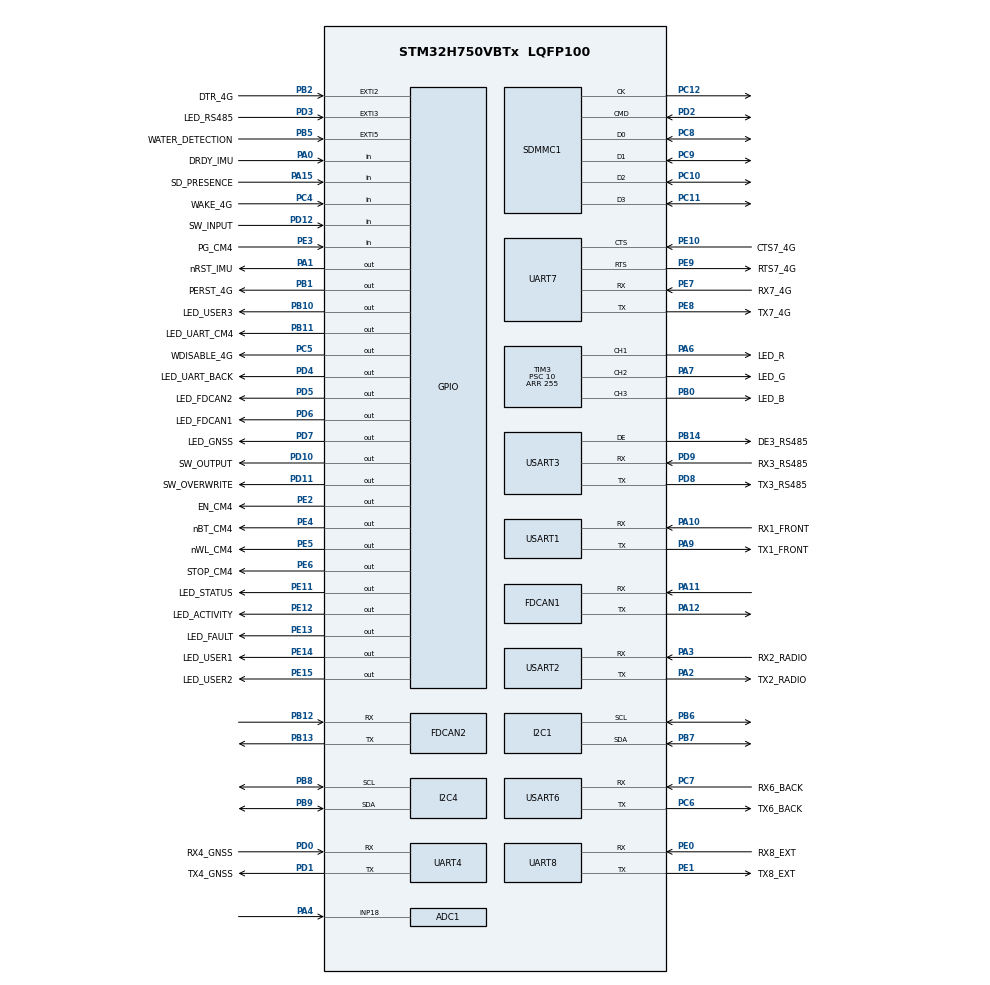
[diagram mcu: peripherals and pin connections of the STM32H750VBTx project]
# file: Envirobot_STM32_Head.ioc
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ADC1.Channel-2\#ChannelRegularConversion=ADC_CHANNEL_18
ADC1.ClockPrescaler=ADC_CLOCK_ASYNC_DIV32
ADC1.NbrOfConversionFlag=1
ADC1.OffsetNumber-2\#ChannelRegularConversion=ADC_OFFSET_NONE
ADC1.OffsetSignedSaturation-2\#ChannelRegularConversion=DISABLE
ADC1.Rank-2\#ChannelRegularConversion=1
ADC1.SamplingTime-2\#ChannelRegularConversion=ADC_SAMPLETIME_16CYCLES_5
ADC1.master=1
ADC3.Channel-0\#ChannelRegularConversion=ADC_CHANNEL_VREFINT
ADC3.ClockPrescaler=ADC_CLOCK_ASYNC_DIV32
ADC3.ClockPrescalerADC3=ADC_CLOCK_ASYNC_DIV32
ADC3.NbrOfConversionFlag=1
ADC3.OffsetNumber-0\#ChannelRegularConversion=ADC_OFFSET_NONE
ADC3.OffsetSignedSaturation-0\#ChannelRegularConversion=DISABLE
ADC3.Rank-0\#ChannelRegularConversion=1
ADC3.Resolution=ADC_RESOLUTION_12B
ADC3.SamplingTime-0\#ChannelRegularConversion=ADC_SAMPLETIME_16CYCLES_5
Dma.I2C1_RX.9.Direction=DMA_PERIPH_TO_MEMORY
Dma.I2C1_RX.9.EventEnable=DISABLE
Dma.I2C1_RX.9.FIFOMode=DMA_FIFOMODE_DISABLE
Dma.I2C1_RX.9.Instance=DMA2_Stream1
Dma.I2C1_RX.9.MemDataAlignment=DMA_MDATAALIGN_BYTE
Dma.I2C1_RX.9.MemInc=DMA_MINC_ENABLE
Dma.I2C1_RX.9.Mode=DMA_NORMAL
Dma.I2C1_RX.9.PeriphDataAlignment=DMA_PDATAALIGN_BYTE
Dma.I2C1_RX.9.PeriphInc=DMA_PINC_DISABLE
Dma.I2C1_RX.9.Polarity=HAL_DMAMUX_REQ_GEN_RISING
Dma.I2C1_RX.9.Priority=DMA_PRIORITY_LOW
Dma.I2C1_RX.9.RequestNumber=1
Dma.I2C1_RX.9.SignalID=NONE
Dma.I2C1_RX.9.SyncEnable=DISABLE
Dma.I2C1_RX.9.SyncPolarity=HAL_DMAMUX_SYNC_NO_EVENT
Dma.I2C1_RX.9.SyncRequestNumber=1
Dma.I2C1_RX.9.SyncSignalID=NONE
Dma.I2C1_TX.8.Direction=DMA_MEMORY_TO_PERIPH
Dma.I2C1_TX.8.EventEnable=DISABLE
Dma.I2C1_TX.8.FIFOMode=DMA_FIFOMODE_DISABLE
Dma.I2C1_TX.8.Instance=DMA2_Stream0
Dma.I2C1_TX.8.MemDataAlignment=DMA_MDATAALIGN_BYTE
Dma.I2C1_TX.8.MemInc=DMA_MINC_ENABLE
Dma.I2C1_TX.8.Mode=DMA_NORMAL
Dma.I2C1_TX.8.PeriphDataAlignment=DMA_PDATAALIGN_BYTE
Dma.I2C1_TX.8.PeriphInc=DMA_PINC_DISABLE
Dma.I2C1_TX.8.Polarity=HAL_DMAMUX_REQ_GEN_RISING
Dma.I2C1_TX.8.Priority=DMA_PRIORITY_LOW
Dma.I2C1_TX.8.RequestNumber=1
Dma.I2C1_TX.8.SignalID=NONE
Dma.I2C1_TX.8.SyncEnable=DISABLE
Dma.I2C1_TX.8.SyncPolarity=HAL_DMAMUX_SYNC_NO_EVENT
Dma.I2C1_TX.8.SyncRequestNumber=1
Dma.I2C1_TX.8.SyncSignalID=NONE
Dma.Request0=USART1_TX
Dma.Request1=USART1_RX
Dma.Request10=UART4_TX
Dma.Request11=UART4_RX
Dma.Request12=UART7_TX
Dma.Request13=UART7_RX
Dma.Request14=UART8_TX
Dma.Request15=UART8_RX
Dma.Request2=USART2_TX
Dma.Request3=USART2_RX
Dma.Request4=USART3_TX
Dma.Request5=USART3_RX
Dma.Request6=USART6_TX
Dma.Request7=USART6_RX
Dma.Request8=I2C1_TX
Dma.Request9=I2C1_RX
Dma.UART4_RX.11.Direction=DMA_PERIPH_TO_MEMORY
Dma.UART4_RX.11.EventEnable=DISABLE
Dma.UART4_RX.11.FIFOMode=DMA_FIFOMODE_DISABLE
Dma.UART4_RX.11.Instance=DMA2_Stream3
Dma.UART4_RX.11.MemDataAlignment=DMA_MDATAALIGN_BYTE
Dma.UART4_RX.11.MemInc=DMA_MINC_ENABLE
Dma.UART4_RX.11.Mode=DMA_CIRCULAR
Dma.UART4_RX.11.PeriphDataAlignment=DMA_PDATAALIGN_BYTE
Dma.UART4_RX.11.PeriphInc=DMA_PINC_DISABLE
Dma.UART4_RX.11.Polarity=HAL_DMAMUX_REQ_GEN_RISING
Dma.UART4_RX.11.Priority=DMA_PRIORITY_LOW
Dma.UART4_RX.11.RequestNumber=1
Dma.UART4_RX.11.SignalID=NONE
Dma.UART4_RX.11.SyncEnable=DISABLE
Dma.UART4_RX.11.SyncPolarity=HAL_DMAMUX_SYNC_NO_EVENT
Dma.UART4_RX.11.SyncRequestNumber=1
Dma.UART4_RX.11.SyncSignalID=NONE
Dma.UART4_TX.10.Direction=DMA_MEMORY_TO_PERIPH
Dma.UART4_TX.10.EventEnable=DISABLE
Dma.UART4_TX.10.FIFOMode=DMA_FIFOMODE_DISABLE
Dma.UART4_TX.10.Instance=DMA2_Stream2
Dma.UART4_TX.10.MemDataAlignment=DMA_MDATAALIGN_BYTE
Dma.UART4_TX.10.MemInc=DMA_MINC_ENABLE
Dma.UART4_TX.10.Mode=DMA_NORMAL
Dma.UART4_TX.10.PeriphDataAlignment=DMA_PDATAALIGN_BYTE
Dma.UART4_TX.10.PeriphInc=DMA_PINC_DISABLE
Dma.UART4_TX.10.Polarity=HAL_DMAMUX_REQ_GEN_RISING
Dma.UART4_TX.10.Priority=DMA_PRIORITY_LOW
Dma.UART4_TX.10.RequestNumber=1
Dma.UART4_TX.10.SignalID=NONE
Dma.UART4_TX.10.SyncEnable=DISABLE
Dma.UART4_TX.10.SyncPolarity=HAL_DMAMUX_SYNC_NO_EVENT
Dma.UART4_TX.10.SyncRequestNumber=1
Dma.UART4_TX.10.SyncSignalID=NONE
Dma.UART7_RX.13.Direction=DMA_PERIPH_TO_MEMORY
Dma.UART7_RX.13.EventEnable=DISABLE
Dma.UART7_RX.13.FIFOMode=DMA_FIFOMODE_DISABLE
Dma.UART7_RX.13.Instance=DMA2_Stream5
Dma.UART7_RX.13.MemDataAlignment=DMA_MDATAALIGN_BYTE
Dma.UART7_RX.13.MemInc=DMA_MINC_ENABLE
Dma.UART7_RX.13.Mode=DMA_CIRCULAR
Dma.UART7_RX.13.PeriphDataAlignment=DMA_PDATAALIGN_BYTE
Dma.UART7_RX.13.PeriphInc=DMA_PINC_DISABLE
Dma.UART7_RX.13.Polarity=HAL_DMAMUX_REQ_GEN_RISING
Dma.UART7_RX.13.Priority=DMA_PRIORITY_LOW
Dma.UART7_RX.13.RequestNumber=1
Dma.UART7_RX.13.SignalID=NONE
Dma.UART7_RX.13.SyncEnable=DISABLE
Dma.UART7_RX.13.SyncPolarity=HAL_DMAMUX_SYNC_NO_EVENT
Dma.UART7_RX.13.SyncRequestNumber=1
Dma.UART7_RX.13.SyncSignalID=NONE
Dma.UART7_TX.12.Direction=DMA_MEMORY_TO_PERIPH
Dma.UART7_TX.12.EventEnable=DISABLE
Dma.UART7_TX.12.FIFOMode=DMA_FIFOMODE_DISABLE
Dma.UART7_TX.12.Instance=DMA2_Stream4
Dma.UART7_TX.12.MemDataAlignment=DMA_MDATAALIGN_BYTE
Dma.UART7_TX.12.MemInc=DMA_MINC_ENABLE
Dma.UART7_TX.12.Mode=DMA_NORMAL
Dma.UART7_TX.12.PeriphDataAlignment=DMA_PDATAALIGN_BYTE
Dma.UART7_TX.12.PeriphInc=DMA_PINC_DISABLE
Dma.UART7_TX.12.Polarity=HAL_DMAMUX_REQ_GEN_RISING
Dma.UART7_TX.12.Priority=DMA_PRIORITY_LOW
Dma.UART7_TX.12.RequestNumber=1
Dma.UART7_TX.12.SignalID=NONE
Dma.UART7_TX.12.SyncEnable=DISABLE
Dma.UART7_TX.12.SyncPolarity=HAL_DMAMUX_SYNC_NO_EVENT
Dma.UART7_TX.12.SyncRequestNumber=1
Dma.UART7_TX.12.SyncSignalID=NONE
Dma.UART8_RX.15.Direction=DMA_PERIPH_TO_MEMORY
Dma.UART8_RX.15.EventEnable=DISABLE
Dma.UART8_RX.15.FIFOMode=DMA_FIFOMODE_DISABLE
Dma.UART8_RX.15.Instance=DMA2_Stream7
Dma.UART8_RX.15.MemDataAlignment=DMA_MDATAALIGN_BYTE
Dma.UART8_RX.15.MemInc=DMA_MINC_ENABLE
Dma.UART8_RX.15.Mode=DMA_CIRCULAR
Dma.UART8_RX.15.PeriphDataAlignment=DMA_PDATAALIGN_BYTE
Dma.UART8_RX.15.PeriphInc=DMA_PINC_DISABLE
Dma.UART8_RX.15.Polarity=HAL_DMAMUX_REQ_GEN_RISING
Dma.UART8_RX.15.Priority=DMA_PRIORITY_LOW
Dma.UART8_RX.15.RequestNumber=1
Dma.UART8_RX.15.SignalID=NONE
Dma.UART8_RX.15.SyncEnable=DISABLE
Dma.UART8_RX.15.SyncPolarity=HAL_DMAMUX_SYNC_NO_EVENT
Dma.UART8_RX.15.SyncRequestNumber=1
Dma.UART8_RX.15.SyncSignalID=NONE
Dma.UART8_TX.14.Direction=DMA_MEMORY_TO_PERIPH
Dma.UART8_TX.14.EventEnable=DISABLE
Dma.UART8_TX.14.FIFOMode=DMA_FIFOMODE_DISABLE
Dma.UART8_TX.14.Instance=DMA2_Stream6
Dma.UART8_TX.14.MemDataAlignment=DMA_MDATAALIGN_BYTE
Dma.UART8_TX.14.MemInc=DMA_MINC_ENABLE
Dma.UART8_TX.14.Mode=DMA_NORMAL
Dma.UART8_TX.14.PeriphDataAlignment=DMA_PDATAALIGN_BYTE
Dma.UART8_TX.14.PeriphInc=DMA_PINC_DISABLE
Dma.UART8_TX.14.Polarity=HAL_DMAMUX_REQ_GEN_RISING
Dma.UART8_TX.14.Priority=DMA_PRIORITY_LOW
Dma.UART8_TX.14.RequestNumber=1
Dma.UART8_TX.14.SignalID=NONE
Dma.UART8_TX.14.SyncEnable=DISABLE
Dma.UART8_TX.14.SyncPolarity=HAL_DMAMUX_SYNC_NO_EVENT
Dma.UART8_TX.14.SyncRequestNumber=1
Dma.UART8_TX.14.SyncSignalID=NONE
Dma.USART1_RX.1.Direction=DMA_PERIPH_TO_MEMORY
Dma.USART1_RX.1.EventEnable=DISABLE
Dma.USART1_RX.1.FIFOMode=DMA_FIFOMODE_DISABLE
Dma.USART1_RX.1.Instance=DMA1_Stream1
Dma.USART1_RX.1.MemDataAlignment=DMA_MDATAALIGN_BYTE
Dma.USART1_RX.1.MemInc=DMA_MINC_ENABLE
Dma.USART1_RX.1.Mode=DMA_CIRCULAR
Dma.USART1_RX.1.PeriphDataAlignment=DMA_PDATAALIGN_BYTE
Dma.USART1_RX.1.PeriphInc=DMA_PINC_DISABLE
Dma.USART1_RX.1.Polarity=HAL_DMAMUX_REQ_GEN_RISING
Dma.USART1_RX.1.Priority=DMA_PRIORITY_LOW
Dma.USART1_RX.1.RequestNumber=1
Dma.USART1_RX.1.SignalID=NONE
Dma.USART1_RX.1.SyncEnable=DISABLE
Dma.USART1_RX.1.SyncPolarity=HAL_DMAMUX_SYNC_NO_EVENT
Dma.USART1_RX.1.SyncRequestNumber=1
Dma.USART1_RX.1.SyncSignalID=NONE
Dma.USART1_TX.0.Direction=DMA_MEMORY_TO_PERIPH
Dma.USART1_TX.0.EventEnable=DISABLE
Dma.USART1_TX.0.FIFOMode=DMA_FIFOMODE_DISABLE
Dma.USART1_TX.0.Instance=DMA1_Stream0
Dma.USART1_TX.0.MemDataAlignment=DMA_MDATAALIGN_BYTE
Dma.USART1_TX.0.MemInc=DMA_MINC_ENABLE
Dma.USART1_TX.0.Mode=DMA_NORMAL
Dma.USART1_TX.0.PeriphDataAlignment=DMA_PDATAALIGN_BYTE
Dma.USART1_TX.0.PeriphInc=DMA_PINC_DISABLE
Dma.USART1_TX.0.Polarity=HAL_DMAMUX_REQ_GEN_RISING
Dma.USART1_TX.0.Priority=DMA_PRIORITY_LOW
Dma.USART1_TX.0.RequestNumber=1
Dma.USART1_TX.0.SignalID=NONE
Dma.USART1_TX.0.SyncEnable=DISABLE
Dma.USART1_TX.0.SyncPolarity=HAL_DMAMUX_SYNC_NO_EVENT
Dma.USART1_TX.0.SyncRequestNumber=1
Dma.USART1_TX.0.SyncSignalID=NONE
Dma.USART2_RX.3.Direction=DMA_PERIPH_TO_MEMORY
Dma.USART2_RX.3.EventEnable=DISABLE
Dma.USART2_RX.3.FIFOMode=DMA_FIFOMODE_DISABLE
Dma.USART2_RX.3.Instance=DMA1_Stream3
Dma.USART2_RX.3.MemDataAlignment=DMA_MDATAALIGN_BYTE
Dma.USART2_RX.3.MemInc=DMA_MINC_ENABLE
Dma.USART2_RX.3.Mode=DMA_CIRCULAR
Dma.USART2_RX.3.PeriphDataAlignment=DMA_PDATAALIGN_BYTE
Dma.USART2_RX.3.PeriphInc=DMA_PINC_DISABLE
Dma.USART2_RX.3.Polarity=HAL_DMAMUX_REQ_GEN_RISING
Dma.USART2_RX.3.Priority=DMA_PRIORITY_LOW
Dma.USART2_RX.3.RequestNumber=1
Dma.USART2_RX.3.SignalID=NONE
Dma.USART2_RX.3.SyncEnable=DISABLE
Dma.USART2_RX.3.SyncPolarity=HAL_DMAMUX_SYNC_NO_EVENT
Dma.USART2_RX.3.SyncRequestNumber=1
Dma.USART2_RX.3.SyncSignalID=NONE
Dma.USART2_TX.2.Direction=DMA_MEMORY_TO_PERIPH
Dma.USART2_TX.2.EventEnable=DISABLE
Dma.USART2_TX.2.FIFOMode=DMA_FIFOMODE_DISABLE
Dma.USART2_TX.2.Instance=DMA1_Stream2
Dma.USART2_TX.2.MemDataAlignment=DMA_MDATAALIGN_BYTE
Dma.USART2_TX.2.MemInc=DMA_MINC_ENABLE
Dma.USART2_TX.2.Mode=DMA_NORMAL
Dma.USART2_TX.2.PeriphDataAlignment=DMA_PDATAALIGN_BYTE
Dma.USART2_TX.2.PeriphInc=DMA_PINC_DISABLE
Dma.USART2_TX.2.Polarity=HAL_DMAMUX_REQ_GEN_RISING
Dma.USART2_TX.2.Priority=DMA_PRIORITY_LOW
Dma.USART2_TX.2.RequestNumber=1
Dma.USART2_TX.2.SignalID=NONE
Dma.USART2_TX.2.SyncEnable=DISABLE
Dma.USART2_TX.2.SyncPolarity=HAL_DMAMUX_SYNC_NO_EVENT
Dma.USART2_TX.2.SyncRequestNumber=1
Dma.USART2_TX.2.SyncSignalID=NONE
Dma.USART3_RX.5.Direction=DMA_PERIPH_TO_MEMORY
Dma.USART3_RX.5.EventEnable=DISABLE
Dma.USART3_RX.5.FIFOMode=DMA_FIFOMODE_DISABLE
Dma.USART3_RX.5.Instance=DMA1_Stream5
Dma.USART3_RX.5.MemDataAlignment=DMA_MDATAALIGN_BYTE
Dma.USART3_RX.5.MemInc=DMA_MINC_ENABLE
Dma.USART3_RX.5.Mode=DMA_CIRCULAR
Dma.USART3_RX.5.PeriphDataAlignment=DMA_PDATAALIGN_BYTE
Dma.USART3_RX.5.PeriphInc=DMA_PINC_DISABLE
Dma.USART3_RX.5.Polarity=HAL_DMAMUX_REQ_GEN_RISING
Dma.USART3_RX.5.Priority=DMA_PRIORITY_LOW
Dma.USART3_RX.5.RequestNumber=1
Dma.USART3_RX.5.SignalID=NONE
Dma.USART3_RX.5.SyncEnable=DISABLE
Dma.USART3_RX.5.SyncPolarity=HAL_DMAMUX_SYNC_NO_EVENT
Dma.USART3_RX.5.SyncRequestNumber=1
Dma.USART3_RX.5.SyncSignalID=NONE
Dma.USART3_TX.4.Direction=DMA_MEMORY_TO_PERIPH
Dma.USART3_TX.4.EventEnable=DISABLE
Dma.USART3_TX.4.FIFOMode=DMA_FIFOMODE_DISABLE
Dma.USART3_TX.4.Instance=DMA1_Stream4
Dma.USART3_TX.4.MemDataAlignment=DMA_MDATAALIGN_BYTE
Dma.USART3_TX.4.MemInc=DMA_MINC_ENABLE
Dma.USART3_TX.4.Mode=DMA_NORMAL
Dma.USART3_TX.4.PeriphDataAlignment=DMA_PDATAALIGN_BYTE
Dma.USART3_TX.4.PeriphInc=DMA_PINC_DISABLE
Dma.USART3_TX.4.Polarity=HAL_DMAMUX_REQ_GEN_RISING
Dma.USART3_TX.4.Priority=DMA_PRIORITY_LOW
Dma.USART3_TX.4.RequestNumber=1
Dma.USART3_TX.4.SignalID=NONE
Dma.USART3_TX.4.SyncEnable=DISABLE
Dma.USART3_TX.4.SyncPolarity=HAL_DMAMUX_SYNC_NO_EVENT
Dma.USART3_TX.4.SyncRequestNumber=1
Dma.USART3_TX.4.SyncSignalID=NONE
Dma.USART6_RX.7.Direction=DMA_PERIPH_TO_MEMORY
Dma.USART6_RX.7.EventEnable=DISABLE
Dma.USART6_RX.7.FIFOMode=DMA_FIFOMODE_DISABLE
Dma.USART6_RX.7.Instance=DMA1_Stream7
Dma.USART6_RX.7.MemDataAlignment=DMA_MDATAALIGN_BYTE
Dma.USART6_RX.7.MemInc=DMA_MINC_ENABLE
Dma.USART6_RX.7.Mode=DMA_CIRCULAR
Dma.USART6_RX.7.PeriphDataAlignment=DMA_PDATAALIGN_BYTE
Dma.USART6_RX.7.PeriphInc=DMA_PINC_DISABLE
Dma.USART6_RX.7.Polarity=HAL_DMAMUX_REQ_GEN_RISING
Dma.USART6_RX.7.Priority=DMA_PRIORITY_LOW
Dma.USART6_RX.7.RequestNumber=1
Dma.USART6_RX.7.SignalID=NONE
Dma.USART6_RX.7.SyncEnable=DISABLE
Dma.USART6_RX.7.SyncPolarity=HAL_DMAMUX_SYNC_NO_EVENT
Dma.USART6_RX.7.SyncRequestNumber=1
Dma.USART6_RX.7.SyncSignalID=NONE
Dma.USART6_TX.6.Direction=DMA_MEMORY_TO_PERIPH
Dma.USART6_TX.6.EventEnable=DISABLE
Dma.USART6_TX.6.FIFOMode=DMA_FIFOMODE_DISABLE
Dma.USART6_TX.6.Instance=DMA1_Stream6
Dma.USART6_TX.6.MemDataAlignment=DMA_MDATAALIGN_BYTE
Dma.USART6_TX.6.MemInc=DMA_MINC_ENABLE
Dma.USART6_TX.6.Mode=DMA_NORMAL
Dma.USART6_TX.6.PeriphDataAlignment=DMA_PDATAALIGN_BYTE
Dma.USART6_TX.6.PeriphInc=DMA_PINC_DISABLE
Dma.USART6_TX.6.Polarity=HAL_DMAMUX_REQ_GEN_RISING
Dma.USART6_TX.6.Priority=DMA_PRIORITY_LOW
Dma.USART6_TX.6.RequestNumber=1
Dma.USART6_TX.6.SignalID=NONE
Dma.USART6_TX.6.SyncEnable=DISABLE
Dma.USART6_TX.6.SyncPolarity=HAL_DMAMUX_SYNC_NO_EVENT
Dma.USART6_TX.6.SyncRequestNumber=1
Dma.USART6_TX.6.SyncSignalID=NONE
FDCAN1.CalculateBaudRateNominal=1000000
FDCAN1.CalculateTimeBitNominal=1000
FDCAN1.CalculateTimeQuantumNominal=10.0
FDCAN1.DataSyncJumpWidth=3
FDCAN1.DataTimeSeg1=21
FDCAN1.DataTimeSeg2=3
FDCAN1.FrameFormat=FDCAN_FRAME_FD_BRS
FDCAN1.NominalPrescaler=1
FDCAN1.NominalSyncJumpWidth=20
FDCAN1.NominalTimeSeg1=79
FDCAN1.NominalTimeSeg2=20
FDCAN1.RxFifo0ElmtSize=FDCAN_DATA_BYTES_64
FDCAN1.RxFifo0ElmtsNbr=10
FDCAN1.RxFifo1ElmtsNbr=0
FDCAN1.StdFiltersNbr=0
FDCAN1.TxElmtSize=FDCAN_DATA_BYTES_64
FDCAN1.TxFifoQueueElmtsNbr=10
FDCAN2.CalculateBaudRateNominal=1000000
FDCAN2.CalculateTimeBitNominal=1000
FDCAN2.CalculateTimeQuantumNominal=10.0
FDCAN2.DataSyncJumpWidth=3
FDCAN2.DataTimeSeg1=21
FDCAN2.DataTimeSeg2=3
FDCAN2.FrameFormat=FDCAN_FRAME_FD_BRS
FDCAN2.MessageRAMOffset=360
FDCAN2.NominalPrescaler=1
FDCAN2.NominalSyncJumpWidth=20
FDCAN2.NominalTimeSeg1=79
FDCAN2.NominalTimeSeg2=20
FDCAN2.RxFifo0ElmtSize=FDCAN_DATA_BYTES_64
FDCAN2.RxFifo0ElmtsNbr=10
FDCAN2.TxElmtSize=FDCAN_DATA_BYTES_64
FDCAN2.TxFifoQueueElmtsNbr=10
FREERTOS.Tasks01=Trajectory,55,512,TrajectoryTask,Default,NULL,Dynamic,NULL,NULL;Sensors,40,512,SensorsTask,Default,NULL,Dynamic,NULL,NULL;Communication,24,512,CommunicationTask,Default,NULL,Dynamic,NULL,NULL;LEDs,8,512,LEDsTask,Default,NULL,Dynamic,NULL,NULL
FREERTOS.configENABLE_FPU=1
FREERTOS.configUSE_NEWLIB_REENTRANT=1
I2C1.Timing=0x307075B1
I2C4.Timing=0x307075B1
Mcu.Family=STM32H7
Mcu.Name=STM32H750VBTx
Mcu.Package=LQFP100
NVIC.DMA1_Stream0_IRQn=true\:5\:0\:false\:false\:true\:true\:false\:true\:true
NVIC.DMA1_Stream1_IRQn=true\:5\:0\:false\:false\:true\:true\:false\:true\:true
NVIC.DMA1_Stream2_IRQn=true\:5\:0\:false\:false\:true\:true\:false\:true\:true
NVIC.DMA1_Stream3_IRQn=true\:5\:0\:false\:false\:true\:true\:false\:true\:true
NVIC.DMA1_Stream4_IRQn=true\:5\:0\:false\:false\:true\:true\:false\:true\:true
NVIC.DMA1_Stream5_IRQn=true\:5\:0\:false\:false\:true\:true\:false\:true\:true
NVIC.DMA1_Stream6_IRQn=true\:5\:0\:false\:false\:true\:true\:false\:true\:true
NVIC.DMA1_Stream7_IRQn=true\:5\:0\:false\:false\:true\:true\:false\:true\:true
NVIC.DMA2_Stream0_IRQn=true\:5\:0\:false\:false\:true\:true\:false\:true\:true
NVIC.DMA2_Stream1_IRQn=true\:5\:0\:false\:false\:true\:true\:false\:true\:true
NVIC.DMA2_Stream2_IRQn=true\:5\:0\:false\:false\:true\:true\:false\:true\:true
NVIC.DMA2_Stream3_IRQn=true\:5\:0\:false\:false\:true\:true\:false\:true\:true
NVIC.DMA2_Stream4_IRQn=true\:5\:0\:false\:false\:true\:true\:false\:true\:true
NVIC.DMA2_Stream5_IRQn=true\:5\:0\:false\:false\:true\:true\:false\:true\:true
NVIC.DMA2_Stream6_IRQn=true\:5\:0\:false\:false\:true\:true\:false\:true\:true
NVIC.DMA2_Stream7_IRQn=true\:5\:0\:false\:false\:true\:true\:false\:true\:true
NVIC.FDCAN1_IT0_IRQn=true\:5\:0\:false\:false\:true\:true\:true\:true\:true
NVIC.FDCAN2_IT0_IRQn=true\:5\:0\:false\:false\:true\:true\:true\:true\:true
NVIC.I2C1_EV_IRQn=true\:5\:0\:false\:false\:true\:true\:true\:true\:true
NVIC.PriorityGroup=NVIC_PRIORITYGROUP_4
NVIC.SDMMC1_IRQn=true\:5\:0\:false\:false\:true\:true\:true\:true\:true
NVIC.TIM4_IRQn=true\:5\:0\:false\:false\:true\:true\:true\:true\:true
NVIC.TIM5_IRQn=true\:0\:0\:true\:false\:true\:false\:false\:true\:true
NVIC.TimeBase=TIM5_IRQn
NVIC.TimeBaseIP=TIM5
NVIC.UART4_IRQn=true\:5\:0\:false\:false\:true\:true\:true\:true\:true
NVIC.UART7_IRQn=true\:5\:0\:false\:false\:true\:true\:true\:true\:true
NVIC.UART8_IRQn=true\:5\:0\:false\:false\:true\:true\:true\:true\:true
NVIC.USART1_IRQn=true\:5\:0\:false\:false\:true\:true\:true\:true\:true
NVIC.USART2_IRQn=true\:5\:0\:false\:false\:true\:true\:true\:true\:true
NVIC.USART3_IRQn=true\:5\:0\:false\:false\:true\:true\:true\:true\:true
NVIC.USART6_IRQn=true\:5\:0\:false\:false\:true\:true\:true\:true\:true
PA0.GPIO_Label=DRDY_IMU
PA0.Signal=GPIO_Input
PA1.GPIO_Label=nRST_IMU
PA1.GPIO_ModeDefaultOutputPP=GPIO_MODE_OUTPUT_OD
PA1.GPIO_PuPd=GPIO_NOPULL
PA1.PinState=GPIO_PIN_SET
PA1.Signal=GPIO_Output
PA10.GPIO_Label=RX1_FRONT
PA10.Mode=Asynchronous
PA10.Signal=USART1_RX
PA11.GPIO_Speed=GPIO_SPEED_FREQ_VERY_HIGH
PA11.Mode=FDCAN_Activate
PA11.Signal=FDCAN1_RX
PA12.GPIO_Speed=GPIO_SPEED_FREQ_VERY_HIGH
PA12.Mode=FDCAN_Activate
PA12.Signal=FDCAN1_TX
PA13\ (JTMS/SWDIO).Mode=Trace_Asynchronous_SW
PA13\ (JTMS/SWDIO).Signal=DEBUG_JTMS-SWDIO
PA14\ (JTCK/SWCLK).Mode=Trace_Asynchronous_SW
PA14\ (JTCK/SWCLK).Signal=DEBUG_JTCK-SWCLK
PA15\ (JTDI).GPIO_Label=SD_PRESENCE
PA15\ (JTDI).Signal=GPIO_Input
PA2.GPIO_Label=TX2_RADIO
PA2.Mode=Asynchronous
PA2.Signal=USART2_TX
PA3.GPIO_Label=RX2_RADIO
PA3.Mode=Asynchronous
PA3.Signal=USART2_RX
PA4.Signal=ADCx_INP18
PA6.GPIO_Label=LED_R
PA6.Signal=S_TIM3_CH1
PA7.GPIO_Label=LED_G
PA7.Signal=S_TIM3_CH2
PA9.GPIO_Label=TX1_FRONT
PA9.Mode=Asynchronous
PA9.Signal=USART1_TX
PB0.GPIO_Label=LED_B
PB0.Signal=S_TIM3_CH3
PB1.GPIO_Label=PERST_4G
PB1.GPIO_ModeDefaultOutputPP=GPIO_MODE_OUTPUT_OD
PB1.GPIO_PuPd=GPIO_NOPULL
PB1.PinState=GPIO_PIN_SET
PB1.Signal=GPIO_Output
PB10.GPIO_Label=LED_USER3
PB10.Signal=GPIO_Output
PB11.GPIO_Label=LED_UART_CM4
PB11.Signal=GPIO_Output
PB12.GPIO_Speed=GPIO_SPEED_FREQ_HIGH
PB12.Mode=FDCAN_Activate
PB12.Signal=FDCAN2_RX
PB13.GPIO_Speed=GPIO_SPEED_FREQ_HIGH
PB13.Mode=FDCAN_Activate
PB13.Signal=FDCAN2_TX
PB14.GPIO_Label=DE3_RS485
PB14.Mode=Hardware Flow Control (RS485)
PB14.Signal=USART3_DE
PB2.GPIO_Label=DTR_4G
PB2.Signal=GPXTI2
PB3\ (JTDO/TRACESWO).Mode=Trace_Asynchronous_SW
PB3\ (JTDO/TRACESWO).Signal=DEBUG_JTDO-SWO
PB5.GPIO_Label=WATER_DETECTION
PB5.Signal=GPXTI5
PB6.Mode=I2C
PB6.Signal=I2C1_SCL
PB7.Mode=I2C
PB7.Signal=I2C1_SDA
PB8.Mode=I2C
PB8.Signal=I2C4_SCL
PB9.Mode=I2C
PB9.Signal=I2C4_SDA
PC10.GPIO_PuPd=GPIO_PULLUP
PC10.Mode=SD_4_bits_Wide_bus
PC10.Signal=SDMMC1_D2
PC11.GPIO_PuPd=GPIO_PULLUP
PC11.Mode=SD_4_bits_Wide_bus
PC11.Signal=SDMMC1_D3
PC12.Mode=SD_4_bits_Wide_bus
PC12.Signal=SDMMC1_CK
PC4.GPIO_Label=WAKE_4G
PC4.GPIO_PuPd=GPIO_PULLUP
PC4.Signal=GPIO_Input
PC5.GPIO_Label=WDISABLE_4G
PC5.GPIO_ModeDefaultOutputPP=GPIO_MODE_OUTPUT_OD
PC5.GPIO_PuPd=GPIO_NOPULL
PC5.PinState=GPIO_PIN_SET
PC5.Signal=GPIO_Output
PC6.GPIO_Label=TX6_BACK
PC6.Mode=Asynchronous
PC6.Signal=USART6_TX
PC7.GPIO_Label=RX6_BACK
PC7.Mode=Asynchronous
PC7.Signal=USART6_RX
PC8.GPIO_PuPd=GPIO_PULLUP
PC8.Mode=SD_4_bits_Wide_bus
PC8.Signal=SDMMC1_D0
PC9.GPIO_PuPd=GPIO_PULLUP
PC9.Mode=SD_4_bits_Wide_bus
PC9.Signal=SDMMC1_D1
PD0.GPIO_Label=RX4_GNSS
PD0.Mode=Asynchronous
PD0.Signal=UART4_RX
PD1.GPIO_Label=TX4_GNSS
PD1.Mode=Asynchronous
PD1.Signal=UART4_TX
PD10.GPIO_Label=SW_OUTPUT
PD10.Signal=GPIO_Output
PD11.GPIO_Label=SW_OVERWRITE
PD11.Signal=GPIO_Output
PD12.GPIO_Label=SW_INPUT
PD12.Signal=GPIO_Input
PD2.GPIO_PuPd=GPIO_PULLUP
PD2.Mode=SD_4_bits_Wide_bus
PD2.Signal=SDMMC1_CMD
PD3.GPIO_Label=LED_RS485
PD3.Signal=GPXTI3
PD4.GPIO_Label=LED_UART_BACK
PD4.Signal=GPIO_Output
PD5.GPIO_Label=LED_FDCAN2
PD5.Signal=GPIO_Output
PD6.GPIO_Label=LED_FDCAN1
PD6.Signal=GPIO_Output
PD7.GPIO_Label=LED_GNSS
PD7.Signal=GPIO_Output
PD8.GPIO_Label=TX3_RS485
PD8.Mode=Asynchronous
PD8.Signal=USART3_TX
PD9.GPIO_Label=RX3_RS485
PD9.Mode=Asynchronous
PD9.Signal=USART3_RX
PE0.GPIO_Label=RX8_EXT
PE0.Mode=Asynchronous
PE0.Signal=UART8_RX
PE1.GPIO_Label=TX8_EXT
PE1.Mode=Asynchronous
PE1.Signal=UART8_TX
PE10.GPIO_Label=CTS7_4G
PE10.Mode=CTS_RTS
PE10.Signal=UART7_CTS
PE11.GPIO_Label=LED_STATUS
PE11.Signal=GPIO_Output
PE12.GPIO_Label=LED_ACTIVITY
PE12.Signal=GPIO_Output
PE13.GPIO_Label=LED_FAULT
PE13.Signal=GPIO_Output
PE14.GPIO_Label=LED_USER1
PE14.Signal=GPIO_Output
PE15.GPIO_Label=LED_USER2
PE15.Signal=GPIO_Output
PE2.GPIO_Label=EN_CM4
PE2.GPIO_ModeDefaultOutputPP=GPIO_MODE_OUTPUT_OD
PE2.GPIO_PuPd=GPIO_NOPULL
PE2.PinState=GPIO_PIN_SET
PE2.Signal=GPIO_Output
PE3.GPIO_Label=PG_CM4
PE3.Signal=GPIO_Input
PE4.GPIO_Label=nBT_CM4
PE4.GPIO_ModeDefaultOutputPP=GPIO_MODE_OUTPUT_OD
PE4.GPIO_PuPd=GPIO_NOPULL
PE4.PinState=GPIO_PIN_SET
PE4.Signal=GPIO_Output
PE5.GPIO_Label=nWL_CM4
PE5.GPIO_ModeDefaultOutputPP=GPIO_MODE_OUTPUT_OD
PE5.GPIO_PuPd=GPIO_NOPULL
PE5.PinState=GPIO_PIN_SET
PE5.Signal=GPIO_Output
PE6.GPIO_Label=STOP_CM4
PE6.Signal=GPIO_Output
PE7.GPIO_Label=RX7_4G
PE7.Mode=Asynchronous
PE7.Signal=UART7_RX
PE8.GPIO_Label=TX7_4G
PE8.Mode=Asynchronous
PE8.Signal=UART7_TX
PE9.GPIO_Label=RTS7_4G
PE9.Mode=CTS_RTS
PE9.Signal=UART7_RTS
PH0-OSC_IN\ (PH0).Mode=HSE-External-Oscillator
PH0-OSC_IN\ (PH0).Signal=RCC_OSC_IN
PH1-OSC_OUT\ (PH1).Mode=HSE-External-Oscillator
PH1-OSC_OUT\ (PH1).Signal=RCC_OSC_OUT
ProjectManager.HeapSize=0x200
ProjectManager.StackSize=0x400
ProjectManager.TargetToolchain=STM32CubeIDE
RCC.ADCCLockSelection=RCC_ADCCLKSOURCE_PLL3
RCC.ADCFreq_Value=160000000
RCC.APB1Freq_Value=120000000
RCC.APB2Freq_Value=120000000
RCC.APB3Freq_Value=120000000
RCC.APB4Freq_Value=120000000
RCC.CortexFreq_Value=480000000
RCC.D1PPRE=RCC_APB3_DIV2
RCC.D2PPRE1=RCC_APB1_DIV2
RCC.D2PPRE2=RCC_APB2_DIV2
RCC.D3PPRE=RCC_APB4_DIV2
RCC.DIVM1=2
RCC.DIVM2=3
RCC.DIVM3=2
RCC.DIVN1=80
RCC.DIVN2=25
RCC.DIVN3=40
RCC.DIVQ1=24
RCC.DIVR1=4
RCC.DIVR3=3
RCC.FDCANCLockSelection=RCC_FDCANCLKSOURCE_PLL2
RCC.FLatency-AdvancedSettings=FLASH_LATENCY_0
RCC.HCLKFreq_Value=240000000
RCC.HPRE=RCC_HCLK_DIV2
RCC.HSE_VALUE=24000000
RCC.PLL1_VCI_Range-AdvancedSettings=RCC_PLL1VCIRANGE_0
RCC.PLL3_VCI_Range-AdvancedSettings=RCC_PLL3VCIRANGE_3
RCC.PLL3_VCO_SEL-AdvancedSettings=RCC_PLL3VCOMEDIUM
RCC.PLLSourceVirtual=RCC_PLLSOURCE_HSE
RCC.SYSCLKFreq_VALUE=480000000
RCC.SYSCLKSource=RCC_SYSCLKSOURCE_PLLCLK
RCC.USBFreq_Value=40000000
SDMMC1.ClockDiv=4
SH.ADCx_INP18.0=ADC1_INP18,IN18-Single-Ended
SH.S_TIM3_CH1.0=TIM3_CH1,PWM Generation1 CH1
SH.S_TIM3_CH2.0=TIM3_CH2,PWM Generation2 CH2
SH.S_TIM3_CH3.0=TIM3_CH3,PWM Generation3 CH3
TIM3.Channel-PWM\ Generation1\ CH1=TIM_CHANNEL_1
TIM3.Channel-PWM\ Generation2\ CH2=TIM_CHANNEL_2
TIM3.Channel-PWM\ Generation3\ CH3=TIM_CHANNEL_3
TIM3.OCPolarity_1=TIM_OCPOLARITY_LOW
TIM3.OCPolarity_2=TIM_OCPOLARITY_LOW
TIM3.OCPolarity_3=TIM_OCPOLARITY_LOW
TIM3.Period=255
TIM3.Prescaler=10
TIM4.ClockDivision=TIM_CLOCKDIVISION_DIV1
TIM4.Period=65535
TIM4.Prescaler=60000
USART1.VirtualMode-Asynchronous=VM_ASYNC
USART2.VirtualMode-Asynchronous=VM_ASYNC
USART3.VirtualMode-Asynchronous=VM_ASYNC
USART3.VirtualMode-Hardware\ Flow\ Control\ (RS485)=VM_ASYNC
USART6.VirtualMode=VM_ASYNC
VP_ADC3_Vref_Input.Mode=IN-Vrefint
VP_FREERTOS_VS_CMSIS_V2.Mode=CMSIS_V2
VP_SYS_VS_tim5.Mode=TIM5
VP_TIM3_VS_ClockSourceINT.Mode=Internal
VP_TIM4_VS_ClockSourceINT.Mode=Internal
board=custom

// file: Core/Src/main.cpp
/* USER CODE BEGIN Header */
/**
  ******************************************************************************
  * @file           : main.c
  * @brief          : Main program body
  ******************************************************************************
  * @attention
  *
  * Copyright (c) 2023 STMicroelectronics.
  * All rights reserved.
  *
  * This software is licensed under terms that can be found in the LICENSE file
  * in the root directory of this software component.
  * If no LICENSE file comes with this software, it is provided AS-IS.
  *
  ******************************************************************************
  */
/* USER CODE END Header */
#include "main.h"
#include "cmsis_os.h"

/* USER CODE BEGIN Includes */
#include "Registers/Registers.hpp"
#include "Protocols/Communication/UART/UARTProtocol.hpp"
#include "Protocols/Communication/FDCAN/CANProtocol.hpp"
#include "Communication/Communication.hpp"
#include "Services/Services.hpp"
#include "Publishers/Publishers.hpp"
#include "Subscribers/MasterSubscribers.hpp"
#include "LEDS/LEDs.hpp"
#include "Sensors/Sensors.hpp"
#include "HardwareDelay/HardwareDelay.hpp"
#include "MotionGenerator/MotionGenerator.hpp"
#include "User.hpp"

#include "PlatformSensors/PlatformSensors.hpp"
#include "PlatformLEDs/PlatformLEDs.hpp"
/* USER CODE END Includes */

ADC_HandleTypeDef hadc1;
ADC_HandleTypeDef hadc3;

FDCAN_HandleTypeDef hfdcan1;
FDCAN_HandleTypeDef hfdcan2;

I2C_HandleTypeDef hi2c1;
I2C_HandleTypeDef hi2c4;
DMA_HandleTypeDef hdma_i2c1_tx;
DMA_HandleTypeDef hdma_i2c1_rx;

SD_HandleTypeDef hsd1;

TIM_HandleTypeDef htim3;
TIM_HandleTypeDef htim4;

UART_HandleTypeDef huart4;
UART_HandleTypeDef huart7;
UART_HandleTypeDef huart8;
UART_HandleTypeDef huart1;
UART_HandleTypeDef huart2;
UART_HandleTypeDef huart3;
UART_HandleTypeDef huart6;
DMA_HandleTypeDef hdma_uart4_tx;
DMA_HandleTypeDef hdma_uart4_rx;
DMA_HandleTypeDef hdma_uart7_tx;
DMA_HandleTypeDef hdma_uart7_rx;
DMA_HandleTypeDef hdma_uart8_tx;
DMA_HandleTypeDef hdma_uart8_rx;
DMA_HandleTypeDef hdma_usart1_tx;
DMA_HandleTypeDef hdma_usart1_rx;
DMA_HandleTypeDef hdma_usart2_tx;
DMA_HandleTypeDef hdma_usart2_rx;
DMA_HandleTypeDef hdma_usart3_tx;
DMA_HandleTypeDef hdma_usart3_rx;
DMA_HandleTypeDef hdma_usart6_tx;
DMA_HandleTypeDef hdma_usart6_rx;

/* Definitions for Trajectory */
osThreadId_t TrajectoryHandle;
const osThreadAttr_t Trajectory_attributes = {
  .name = "Trajectory",
  .stack_size = 512 * 4,
  .priority = (osPriority_t) osPriorityRealtime7,
};
/* Definitions for Sensors */
osThreadId_t SensorsHandle;
const osThreadAttr_t Sensors_attributes = {
  .name = "Sensors",
  .stack_size = 512 * 4,
  .priority = (osPriority_t) osPriorityHigh,
};
/* Definitions for Communication */
osThreadId_t CommunicationHandle;
const osThreadAttr_t Communication_attributes = {
  .name = "Communication",
  .stack_size = 512 * 4,
  .priority = (osPriority_t) osPriorityNormal,
};
/* Definitions for LEDs */
osThreadId_t LEDsHandle;
const osThreadAttr_t LEDs_attributes = {
  .name = "LEDs",
  .stack_size = 512 * 4,
  .priority = (osPriority_t) osPriorityLow,
};

void SystemClock_Config(void);
void PeriphCommonClock_Config(void);
static void MX_GPIO_Init(void);
static void MX_DMA_Init(void);
static void MX_ADC1_Init(void);
static void MX_FDCAN1_Init(void);
static void MX_FDCAN2_Init(void);
static void MX_I2C1_Init(void);
static void MX_I2C4_Init(void);
static void MX_USART1_UART_Init(void);
static void MX_USART2_UART_Init(void);
static void MX_USART3_UART_Init(void);
static void MX_USART6_UART_Init(void);
static void MX_TIM4_Init(void);
static void MX_ADC3_Init(void);
static void MX_UART4_Init(void);
static void MX_UART8_Init(void);
static void MX_UART7_Init(void);
static void MX_SDMMC1_SD_Init(void);
static void MX_TIM3_Init(void);
void TrajectoryTask(void *argument);
void SensorsTask(void *argument);
void CommunicationTask(void *argument);
void LEDsTask(void *argument);

/* USER CODE BEGIN 0 */

Registers registers;
UARTProtocol protocol_uart;
CANProtocol protocol_canfd;
MasterSubscribers subscribers;
Communication communication;
Services services;
Publishers publishers;
HardwareDelay hardware_delay(&htim4);
Sensors sensors;
LEDS leds;
MotionGenerator motion_generator;

PlatformSensors platform_sensors;

User user(&registers, &subscribers, &communication, &services, &publishers, &hardware_delay, &sensors, &leds);

// UART Callback at IDLE, DMA Half-tranfer and DMA complete-transfer
void HAL_UARTEx_RxEventCallback(UART_HandleTypeDef *huart, uint16_t Size) {
	std::vector<uint8_t> received_data;
	uint8_t ID;

	bool success;
	ID = communication.GetID((void*) huart, &success);
	if (!success) {return;}

	std::vector<uint8_t>* buffer = communication.GetBuffer(ID, &success);
	uint16_t* buffer_index = communication.GetBufferIndex(ID, &success);

	if (!success) {communication.ActivateReception(ID); return;}

	// Check there is something to process. This can happend when the DMA interrupt occur at the same index as the IDLE. The second interrupt will have nothing to process. One should avoid a complete buffer process in this case
	if (Size == *buffer_index) {communication.ActivateReception(ID); return;}

	if (Size > *buffer_index)
		received_data = std::vector<uint8_t>(buffer->begin() + *buffer_index, buffer->begin() + Size);
	else {  // it means that the beginning of the data is at the end of the buffer, and the end at the beginning
		received_data = std::vector<uint8_t>(buffer->begin() + *buffer_index, buffer->end());
		received_data.insert(received_data.end(), buffer->begin(), buffer->begin() + Size);
	}

	uint16_t processed_length = communication.Process(ID, received_data, &success);
	*buffer_index += processed_length;
	if (*buffer_index >= buffer->size())
		*buffer_index -= buffer->size();

	communication.ActivateReception(ID);
}

// UART Error callback
void HAL_UART_ErrorCallback(UART_HandleTypeDef *huart) {
	bool success;
	uint8_t ID = communication.GetID((void*) huart, &success);
	if (!success) {return;}

	uint16_t* buffer_index = communication.GetBufferIndex(ID, &success);

	*buffer_index = 0; // resets the buffer index to the DMA pointer
	communication.ActivateReception(ID);
}

// FDCAN callback
void HAL_FDCAN_RxFifo0Callback(FDCAN_HandleTypeDef *hfdcan, uint32_t RxFifo0ITs) {
	if((RxFifo0ITs & FDCAN_IT_RX_FIFO0_NEW_MESSAGE) != RESET) {
		uint8_t ID;
		FDCAN_RxHeaderTypeDef RxHeader;
		uint8_t RxData[64];

		/* Retreive Rx messages from RX FIFO0 */
	    HAL_FDCAN_GetRxMessage(hfdcan, FDCAN_RX_FIFO0, &RxHeader, RxData);

	    bool success;
		ID = communication.GetID((void*) hfdcan, &success);
		if (!success) {communication.ActivateReception(ID); return;}

	    uint8_t target_address = (uint8_t) RxHeader.Identifier;
		std::vector<uint8_t> received_data(RxData, RxData + 64);
		received_data.insert(received_data.begin(), target_address);

		communication.Process(ID, received_data, &success);

		communication.ActivateReception(ID);
	}
}

// FDCAN Error callback
void HAL_FDCAN_ErrorCallback(FDCAN_HandleTypeDef *hfdcan) {
	bool success;
	uint8_t ID = communication.GetID((void*) hfdcan, &success);
	if (!success) {return;}

	communication.ActivateReception(ID);
}

// I2C Memory Access Callback
void HAL_I2C_MemRxCpltCallback(I2C_HandleTypeDef *hi2c) {
	sensors.ReceiveSensorData(hi2c);
}

// I2C Master Write Callback
void HAL_I2C_MasterTxCpltCallback(I2C_HandleTypeDef *hi2c) {
	sensors.ReceiveSensorData(hi2c);
}

// I2C Master Read Callback
void HAL_I2C_MasterRxCpltCallback(I2C_HandleTypeDef *hi2c) {
	sensors.ReceiveSensorData(hi2c);
}

// External Interrupt Callback
void HAL_GPIO_EXTI_Callback(uint16_t GPIO_Pin)
{
    if(GPIO_Pin == WATER_DETECTION_Pin) // Trigger fault LED and set RGB led to blue when water detected
    {
    	WaterDetectedLEDS(&leds);
    }
}

/* USER CODE END 0 */

int main(void)
{

  /* MCU Configuration--------------------------------------------------------*/

  /* Reset of all peripherals, Initializes the Flash interface and the Systick. */
  HAL_Init();

  /* Configure the system clock */
  SystemClock_Config();

/* Configure the peripherals common clocks */
  PeriphCommonClock_Config();

  /* Initialize all configured peripherals */
  MX_GPIO_Init();
  MX_DMA_Init();
  MX_ADC1_Init();
  MX_FDCAN1_Init();
  MX_FDCAN2_Init();
  MX_I2C1_Init();
  MX_I2C4_Init();
  MX_USART1_UART_Init();
  MX_USART2_UART_Init();
  MX_USART3_UART_Init();
  MX_USART6_UART_Init();
  MX_TIM4_Init();
  MX_ADC3_Init();
  MX_UART4_Init();
  MX_UART8_Init();
  MX_UART7_Init();
  MX_SDMMC1_SD_Init();
  MX_TIM3_Init();
  /* USER CODE BEGIN 2 */

  // ADC Calibration
  HAL_ADCEx_Calibration_Start(&hadc1, ADC_CALIB_OFFSET, ADC_SINGLE_ENDED);
  HAL_ADCEx_Calibration_Start(&hadc3, ADC_CALIB_OFFSET, ADC_SINGLE_ENDED);

  registers.Init();
  leds.Init(&registers);
  registers.Init(); 																registers.AddBaseRegisters();
  communication.Init(&registers, &services, &subscribers, &leds);					communication.AddRegisters();
  services.Init(&registers, &communication, &leds);
  publishers.Init(&registers, &communication); 										publishers.AddRegisters();
  subscribers.Init(&registers, &leds);												subscribers.AddRegisters();
  sensors.Init(&registers, &publishers, &hardware_delay, &leds);					sensors.AddRegisters();
  leds.Init(&registers);															leds.AddRegisters();
  motion_generator.Init(&registers, &publishers, &services, &leds);					motion_generator.AddRegisters();

  //////////
  // LEDs //
  //////////
#ifdef USE_LEDS
#ifdef USE_SMD_LEDs
  HAL_TIM_PWM_Start(&htim3, TIM_CHANNEL_1); 			// R LED
  HAL_TIM_PWM_Start(&htim3, TIM_CHANNEL_2); 			// G LED
  HAL_TIM_PWM_Start(&htim3, TIM_CHANNEL_3); 			// B LED

  leds.AddLED(LED_UART_RS485, GPIO {LED_RS485_GPIO_Port, LED_RS485_Pin});
  leds.AddLED(LED_UART_BACK, GPIO {LED_UART_BACK_GPIO_Port, LED_UART_BACK_Pin});
  leds.AddLED(LED_CANFD2, GPIO {LED_FDCAN2_GPIO_Port, LED_FDCAN2_Pin});
  leds.AddLED(LED_CANFD1, GPIO {LED_FDCAN1_GPIO_Port, LED_FDCAN1_Pin});
  leds.AddLED(LED_UART_CM4, GPIO {LED_UART_CM4_GPIO_Port, LED_UART_CM4_Pin});

  leds.AddLED(LED_STATUS, GPIO {LED_STATUS_GPIO_Port, LED_STATUS_Pin});
  leds.AddLED(LED_ACTIVITY, GPIO {LED_ACTIVITY_GPIO_Port, LED_ACTIVITY_Pin});
  leds.AddLED(LED_FAULT, GPIO {LED_FAULT_GPIO_Port, LED_FAULT_Pin});
  leds.AddLED(LED_USER1, GPIO {LED_USER1_GPIO_Port, LED_USER1_Pin});
  leds.AddLED(LED_USER2, GPIO {LED_USER2_GPIO_Port, LED_USER2_Pin});
  leds.AddLED(LED_USER3, GPIO {LED_USER3_GPIO_Port, LED_USER3_Pin});

  leds.ConfigureTimings(LED_CANFD1, std::vector<uint8_t>{1}, 2);
  leds.ConfigureTimings(LED_CANFD2, std::vector<uint8_t>{1}, 2);
  leds.ConfigureTimings(LED_UART_CM4, std::vector<uint8_t>{1}, 2);
  leds.ConfigureTimings(LED_UART_BACK, std::vector<uint8_t>{1}, 2);
  leds.ConfigureTimings(LED_UART_RS485, std::vector<uint8_t>{1}, 2);

  leds.AddRGBLED(LED_RGB, const_cast<uint32_t*>(&(TIM3->CCR1)), const_cast<uint32_t*>(&(TIM3->CCR2)), const_cast<uint32_t*>(&(TIM3->CCR3)));
#endif

#ifdef TEST_LEDS
  leds.TestLEDs();
#endif
  StartupLEDS(&leds);
#endif

  //////////////////////////
  // Trajectory Generator //
  //////////////////////////
#ifdef USE_MOTION_GENERATOR
  motion_generator.SetupPublisher();
#ifdef GENERATOR_ACTIVE
  motion_generator.ActivateGenerator();
#endif
#endif

  ///////////////////
  // Communication //
  ///////////////////
  communication.SetModuleAddress(STM32_HEAD);

  /* UART Protocol */
#if defined(USE_UART_FRONT) || defined (USE_UART_BACK) || defined (USE_RS485) || defined (USE_UART_PIC) || defined (USE_UART_EXTENSION)
  protocol_uart.SetProtocolPayloadMaxLength(256);

#ifdef USE_UART_CM4
  protocol_uart.AddInterface(UART_CM4, &huart1);
#endif
#ifdef USE_UART_BACK
  protocol_uart.AddInterface(UART_BACK, &huart6);
#endif
#ifdef USE_RS485
  protocol_uart.AddInterface(UART_RS485, &huart3);
  protocol_uart.SetAsRS485(UART_RS485);
#endif
#ifdef USE_UART_PIC
  protocol_uart.AddInterface(UART_PIC, &huart2);
#endif
#ifdef USE_UART_EXTENSION
  protocol_uart.AddInterface(UART_EXTENSION, &huart8);
#endif

  communication.AddProtocol(&protocol_uart);

#ifdef USE_UART_CM4
  communication.ActivateReception(UART_CM4);
#endif
#ifdef USE_UART_BACK
  communication.ActivateReception(UART_BACK);
#endif
#ifdef USE_RS485
  communication.ActivateReception(UART_RS485);
#endif
#ifdef USE_UART_PIC
  communication.ActivateReception(UART_PIC);
#endif
#ifdef USE_UART_EXTENSION
  communication.ActivateReception(UART_EXTENSION);
#endif
#endif

  /* CANFD Protocol */
#if defined(USE_FDCAN1) || defined (USE_FDCAN2)
  protocol_canfd.SetProtocolPayloadMaxLength(62);

#ifdef USE_FDCAN1
  protocol_canfd.AddInterface(CANFD1, &hfdcan1);
  protocol_canfd.ConfigureFilters(CANFD1);
  protocol_canfd.ActivateReception(CANFD1);
  protocol_canfd.Start(CANFD1);
#endif
#ifdef USE_FDCAN2
  protocol_canfd.AddInterface(CANFD2, &hfdcan2);
  protocol_canfd.ConfigureFilters(CANFD2);
  protocol_canfd.ActivateReception(CANFD2);
  protocol_canfd.Start(CANFD2);
#endif

  communication.AddProtocol(&protocol_canfd);

#ifdef USE_FDCAN1
  communication.ActivateReception(CANFD1);
#endif
#ifdef USE_FDCAN2
  communication.ActivateReception(CANFD2);
#endif
#endif

  /////////////
  // SENSORS //
  /////////////
#ifdef USE_SENSORS
  platform_sensors.Init(&sensors, &registers, &publishers, &leds);

  HAL_Delay(2000); // leave some time to the power PIC to configure the DS2778. This can be optimized by monitoring the PIC and wait until configuration is complete.

  sensors.AddInterface(I2C1_ID, &hi2c1);
  sensors.AddInterface(INTERNAL, NULL);

  // ADC measures
#ifdef USE_ADCs
  platform_sensors.AddVoltageSensor(&hadc3, &hadc1);
  platform_sensors.ActivateVoltageSensor();
  platform_sensors.SetupVoltageSensorPublisher();
#endif

  HAL_Delay(10);

#ifdef READ_SENSORS
  sensors.ActivateReading();
#endif

  HAL_Delay(10);

#endif

  user.Init();

  /* USER CODE END 2 */

  /* Init scheduler */
  osKernelInitialize();

  /* Create the thread(s) */
  /* creation of Trajectory */
  TrajectoryHandle = osThreadNew(TrajectoryTask, NULL, &Trajectory_attributes);

  /* creation of Sensors */
  SensorsHandle = osThreadNew(SensorsTask, NULL, &Sensors_attributes);

  /* creation of Communication */
  CommunicationHandle = osThreadNew(CommunicationTask, NULL, &Communication_attributes);

  /* creation of LEDs */
  LEDsHandle = osThreadNew(LEDsTask, NULL, &LEDs_attributes);

  /* USER CODE BEGIN RTOS_THREADS */
  /* add threads, ... */
  user.AddOSThreads();
  /* USER CODE END RTOS_THREADS */

  /* Start scheduler */
  osKernelStart();

  /* We should never get here as control is now taken by the scheduler */
  /* Infinite loop */
  while (1)
  {

  }
}

void SystemClock_Config(void)
{
  RCC_OscInitTypeDef RCC_OscInitStruct = {0};
  RCC_ClkInitTypeDef RCC_ClkInitStruct = {0};

  /** Supply configuration update enable
  */
  HAL_PWREx_ConfigSupply(PWR_LDO_SUPPLY);

  /** Configure the main internal regulator output voltage
  */
  __HAL_PWR_VOLTAGESCALING_CONFIG(PWR_REGULATOR_VOLTAGE_SCALE1);

  while(!__HAL_PWR_GET_FLAG(PWR_FLAG_VOSRDY)) {}

  __HAL_RCC_SYSCFG_CLK_ENABLE();
  __HAL_PWR_VOLTAGESCALING_CONFIG(PWR_REGULATOR_VOLTAGE_SCALE0);

  while(!__HAL_PWR_GET_FLAG(PWR_FLAG_VOSRDY)) {}

  /** Macro to configure the PLL clock source
  */
  __HAL_RCC_PLL_PLLSOURCE_CONFIG(RCC_PLLSOURCE_HSE);

  /** Initializes the RCC Oscillators according to the specified parameters
  * in the RCC_OscInitTypeDef structure.
  */
  RCC_OscInitStruct.OscillatorType = RCC_OSCILLATORTYPE_HSE;
  RCC_OscInitStruct.HSEState = RCC_HSE_ON;
  RCC_OscInitStruct.PLL.PLLState = RCC_PLL_ON;
  RCC_OscInitStruct.PLL.PLLSource = RCC_PLLSOURCE_HSE;
  RCC_OscInitStruct.PLL.PLLM = 2;
  RCC_OscInitStruct.PLL.PLLN = 80;
  RCC_OscInitStruct.PLL.PLLP = 2;
  RCC_OscInitStruct.PLL.PLLQ = 24;
  RCC_OscInitStruct.PLL.PLLR = 4;
  RCC_OscInitStruct.PLL.PLLRGE = RCC_PLL1VCIRANGE_3;
  RCC_OscInitStruct.PLL.PLLVCOSEL = RCC_PLL1VCOWIDE;
  RCC_OscInitStruct.PLL.PLLFRACN = 0;
  if (HAL_RCC_OscConfig(&RCC_OscInitStruct) != HAL_OK)
  {
    Error_Handler();
  }

  /** Initializes the CPU, AHB and APB buses clocks
  */
  RCC_ClkInitStruct.ClockType = RCC_CLOCKTYPE_HCLK|RCC_CLOCKTYPE_SYSCLK
                              |RCC_CLOCKTYPE_PCLK1|RCC_CLOCKTYPE_PCLK2
                              |RCC_CLOCKTYPE_D3PCLK1|RCC_CLOCKTYPE_D1PCLK1;
  RCC_ClkInitStruct.SYSCLKSource = RCC_SYSCLKSOURCE_PLLCLK;
  RCC_ClkInitStruct.SYSCLKDivider = RCC_SYSCLK_DIV1;
  RCC_ClkInitStruct.AHBCLKDivider = RCC_HCLK_DIV2;
  RCC_ClkInitStruct.APB3CLKDivider = RCC_APB3_DIV2;
  RCC_ClkInitStruct.APB1CLKDivider = RCC_APB1_DIV2;
  RCC_ClkInitStruct.APB2CLKDivider = RCC_APB2_DIV2;
  RCC_ClkInitStruct.APB4CLKDivider = RCC_APB4_DIV2;

  if (HAL_RCC_ClockConfig(&RCC_ClkInitStruct, FLASH_LATENCY_4) != HAL_OK)
  {
    Error_Handler();
  }
}

void PeriphCommonClock_Config(void)
{
  RCC_PeriphCLKInitTypeDef PeriphClkInitStruct = {0};

  /** Initializes the peripherals clock
  */
  PeriphClkInitStruct.PeriphClockSelection = RCC_PERIPHCLK_ADC|RCC_PERIPHCLK_FDCAN;
  PeriphClkInitStruct.PLL2.PLL2M = 3;
  PeriphClkInitStruct.PLL2.PLL2N = 25;
  PeriphClkInitStruct.PLL2.PLL2P = 2;
  PeriphClkInitStruct.PLL2.PLL2Q = 2;
  PeriphClkInitStruct.PLL2.PLL2R = 2;
  PeriphClkInitStruct.PLL2.PLL2RGE = RCC_PLL2VCIRANGE_3;
  PeriphClkInitStruct.PLL2.PLL2VCOSEL = RCC_PLL2VCOWIDE;
  PeriphClkInitStruct.PLL2.PLL2FRACN = 0;
  PeriphClkInitStruct.PLL3.PLL3M = 2;
  PeriphClkInitStruct.PLL3.PLL3N = 40;
  PeriphClkInitStruct.PLL3.PLL3P = 2;
  PeriphClkInitStruct.PLL3.PLL3Q = 2;
  PeriphClkInitStruct.PLL3.PLL3R = 3;
  PeriphClkInitStruct.PLL3.PLL3RGE = RCC_PLL3VCIRANGE_3;
  PeriphClkInitStruct.PLL3.PLL3VCOSEL = RCC_PLL3VCOWIDE;
  PeriphClkInitStruct.PLL3.PLL3FRACN = 0;
  PeriphClkInitStruct.FdcanClockSelection = RCC_FDCANCLKSOURCE_PLL2;
  PeriphClkInitStruct.AdcClockSelection = RCC_ADCCLKSOURCE_PLL3;
  if (HAL_RCCEx_PeriphCLKConfig(&PeriphClkInitStruct) != HAL_OK)
  {
    Error_Handler();
  }
}

static void MX_ADC1_Init(void)
{

  ADC_MultiModeTypeDef multimode = {0};
  ADC_ChannelConfTypeDef sConfig = {0};

  /** Common config
  */
  hadc1.Instance = ADC1;
  hadc1.Init.ClockPrescaler = ADC_CLOCK_ASYNC_DIV32;
  hadc1.Init.Resolution = ADC_RESOLUTION_16B;
  hadc1.Init.ScanConvMode = ADC_SCAN_DISABLE;
  hadc1.Init.EOCSelection = ADC_EOC_SINGLE_CONV;
  hadc1.Init.LowPowerAutoWait = DISABLE;
  hadc1.Init.ContinuousConvMode = DISABLE;
  hadc1.Init.NbrOfConversion = 1;
  hadc1.Init.DiscontinuousConvMode = DISABLE;
  hadc1.Init.ExternalTrigConv = ADC_SOFTWARE_START;
  hadc1.Init.ExternalTrigConvEdge = ADC_EXTERNALTRIGCONVEDGE_NONE;
  hadc1.Init.ConversionDataManagement = ADC_CONVERSIONDATA_DR;
  hadc1.Init.Overrun = ADC_OVR_DATA_PRESERVED;
  hadc1.Init.LeftBitShift = ADC_LEFTBITSHIFT_NONE;
  hadc1.Init.OversamplingMode = DISABLE;
  if (HAL_ADC_Init(&hadc1) != HAL_OK)
  {
    Error_Handler();
  }

  /** Configure the ADC multi-mode
  */
  multimode.Mode = ADC_MODE_INDEPENDENT;
  if (HAL_ADCEx_MultiModeConfigChannel(&hadc1, &multimode) != HAL_OK)
  {
    Error_Handler();
  }

  /** Configure Regular Channel
  */
  sConfig.Channel = ADC_CHANNEL_18;
  sConfig.Rank = ADC_REGULAR_RANK_1;
  sConfig.SamplingTime = ADC_SAMPLETIME_16CYCLES_5;
  sConfig.SingleDiff = ADC_SINGLE_ENDED;
  sConfig.OffsetNumber = ADC_OFFSET_NONE;
  sConfig.Offset = 0;
  sConfig.OffsetSignedSaturation = DISABLE;
  if (HAL_ADC_ConfigChannel(&hadc1, &sConfig) != HAL_OK)
  {
    Error_Handler();
  }

}

static void MX_ADC3_Init(void)
{

  ADC_ChannelConfTypeDef sConfig = {0};

  /** Common config
  */
  hadc3.Instance = ADC3;
  hadc3.Init.ClockPrescaler = ADC_CLOCK_ASYNC_DIV32;
  hadc3.Init.Resolution = ADC_RESOLUTION_12B;
  hadc3.Init.ScanConvMode = ADC_SCAN_DISABLE;
  hadc3.Init.EOCSelection = ADC_EOC_SINGLE_CONV;
  hadc3.Init.LowPowerAutoWait = DISABLE;
  hadc3.Init.ContinuousConvMode = DISABLE;
  hadc3.Init.NbrOfConversion = 1;
  hadc3.Init.DiscontinuousConvMode = DISABLE;
  hadc3.Init.ExternalTrigConv = ADC_SOFTWARE_START;
  hadc3.Init.ExternalTrigConvEdge = ADC_EXTERNALTRIGCONVEDGE_NONE;
  hadc3.Init.ConversionDataManagement = ADC_CONVERSIONDATA_DR;
  hadc3.Init.Overrun = ADC_OVR_DATA_PRESERVED;
  hadc3.Init.LeftBitShift = ADC_LEFTBITSHIFT_NONE;
  hadc3.Init.OversamplingMode = DISABLE;
  if (HAL_ADC_Init(&hadc3) != HAL_OK)
  {
    Error_Handler();
  }

  /** Configure Regular Channel
  */
  sConfig.Channel = ADC_CHANNEL_VREFINT;
  sConfig.Rank = ADC_REGULAR_RANK_1;
  sConfig.SamplingTime = ADC_SAMPLETIME_16CYCLES_5;
  sConfig.SingleDiff = ADC_SINGLE_ENDED;
  sConfig.OffsetNumber = ADC_OFFSET_NONE;
  sConfig.Offset = 0;
  sConfig.OffsetSignedSaturation = DISABLE;
  if (HAL_ADC_ConfigChannel(&hadc3, &sConfig) != HAL_OK)
  {
    Error_Handler();
  }

}

static void MX_FDCAN1_Init(void)
{

  hfdcan1.Instance = FDCAN1;
  hfdcan1.Init.FrameFormat = FDCAN_FRAME_FD_BRS;
  hfdcan1.Init.Mode = FDCAN_MODE_NORMAL;
  hfdcan1.Init.AutoRetransmission = DISABLE;
  hfdcan1.Init.TransmitPause = DISABLE;
  hfdcan1.Init.ProtocolException = DISABLE;
  hfdcan1.Init.NominalPrescaler = 1;
  hfdcan1.Init.NominalSyncJumpWidth = 20;
  hfdcan1.Init.NominalTimeSeg1 = 79;
  hfdcan1.Init.NominalTimeSeg2 = 20;
  hfdcan1.Init.DataPrescaler = 1;
  hfdcan1.Init.DataSyncJumpWidth = 3;
  hfdcan1.Init.DataTimeSeg1 = 21;
  hfdcan1.Init.DataTimeSeg2 = 3;
  hfdcan1.Init.MessageRAMOffset = 0;
  hfdcan1.Init.StdFiltersNbr = 0;
  hfdcan1.Init.ExtFiltersNbr = 0;
  hfdcan1.Init.RxFifo0ElmtsNbr = 10;
  hfdcan1.Init.RxFifo0ElmtSize = FDCAN_DATA_BYTES_64;
  hfdcan1.Init.RxFifo1ElmtsNbr = 0;
  hfdcan1.Init.RxFifo1ElmtSize = FDCAN_DATA_BYTES_8;
  hfdcan1.Init.RxBuffersNbr = 0;
  hfdcan1.Init.RxBufferSize = FDCAN_DATA_BYTES_8;
  hfdcan1.Init.TxEventsNbr = 0;
  hfdcan1.Init.TxBuffersNbr = 0;
  hfdcan1.Init.TxFifoQueueElmtsNbr = 10;
  hfdcan1.Init.TxFifoQueueMode = FDCAN_TX_FIFO_OPERATION;
  hfdcan1.Init.TxElmtSize = FDCAN_DATA_BYTES_64;
  if (HAL_FDCAN_Init(&hfdcan1) != HAL_OK)
  {
    Error_Handler();
  }

}

static void MX_FDCAN2_Init(void)
{

  hfdcan2.Instance = FDCAN2;
  hfdcan2.Init.FrameFormat = FDCAN_FRAME_FD_BRS;
  hfdcan2.Init.Mode = FDCAN_MODE_NORMAL;
  hfdcan2.Init.AutoRetransmission = DISABLE;
  hfdcan2.Init.TransmitPause = DISABLE;
  hfdcan2.Init.ProtocolException = DISABLE;
  hfdcan2.Init.NominalPrescaler = 1;
  hfdcan2.Init.NominalSyncJumpWidth = 20;
  hfdcan2.Init.NominalTimeSeg1 = 79;
  hfdcan2.Init.NominalTimeSeg2 = 20;
  hfdcan2.Init.DataPrescaler = 1;
  hfdcan2.Init.DataSyncJumpWidth = 3;
  hfdcan2.Init.DataTimeSeg1 = 21;
  hfdcan2.Init.DataTimeSeg2 = 3;
  hfdcan2.Init.MessageRAMOffset = 360;
  hfdcan2.Init.StdFiltersNbr = 0;
  hfdcan2.Init.ExtFiltersNbr = 0;
  hfdcan2.Init.RxFifo0ElmtsNbr = 10;
  hfdcan2.Init.RxFifo0ElmtSize = FDCAN_DATA_BYTES_64;
  hfdcan2.Init.RxFifo1ElmtsNbr = 0;
  hfdcan2.Init.RxFifo1ElmtSize = FDCAN_DATA_BYTES_8;
  hfdcan2.Init.RxBuffersNbr = 0;
  hfdcan2.Init.RxBufferSize = FDCAN_DATA_BYTES_8;
  hfdcan2.Init.TxEventsNbr = 0;
  hfdcan2.Init.TxBuffersNbr = 0;
  hfdcan2.Init.TxFifoQueueElmtsNbr = 10;
  hfdcan2.Init.TxFifoQueueMode = FDCAN_TX_FIFO_OPERATION;
  hfdcan2.Init.TxElmtSize = FDCAN_DATA_BYTES_64;
  if (HAL_FDCAN_Init(&hfdcan2) != HAL_OK)
  {
    Error_Handler();
  }

}

static void MX_I2C1_Init(void)
{

  hi2c1.Instance = I2C1;
  hi2c1.Init.Timing = 0x307075B1;
  hi2c1.Init.OwnAddress1 = 0;
  hi2c1.Init.AddressingMode = I2C_ADDRESSINGMODE_7BIT;
  hi2c1.Init.DualAddressMode = I2C_DUALADDRESS_DISABLE;
  hi2c1.Init.OwnAddress2 = 0;
  hi2c1.Init.OwnAddress2Masks = I2C_OA2_NOMASK;
  hi2c1.Init.GeneralCallMode = I2C_GENERALCALL_DISABLE;
  hi2c1.Init.NoStretchMode = I2C_NOSTRETCH_DISABLE;
  if (HAL_I2C_Init(&hi2c1) != HAL_OK)
  {
    Error_Handler();
  }

  /** Configure Analogue filter
  */
  if (HAL_I2CEx_ConfigAnalogFilter(&hi2c1, I2C_ANALOGFILTER_ENABLE) != HAL_OK)
  {
    Error_Handler();
  }

  /** Configure Digital filter
  */
  if (HAL_I2CEx_ConfigDigitalFilter(&hi2c1, 0) != HAL_OK)
  {
    Error_Handler();
  }

}

static void MX_I2C4_Init(void)
{

  hi2c4.Instance = I2C4;
  hi2c4.Init.Timing = 0x307075B1;
  hi2c4.Init.OwnAddress1 = 0;
  hi2c4.Init.AddressingMode = I2C_ADDRESSINGMODE_7BIT;
  hi2c4.Init.DualAddressMode = I2C_DUALADDRESS_DISABLE;
  hi2c4.Init.OwnAddress2 = 0;
  hi2c4.Init.OwnAddress2Masks = I2C_OA2_NOMASK;
  hi2c4.Init.GeneralCallMode = I2C_GENERALCALL_DISABLE;
  hi2c4.Init.NoStretchMode = I2C_NOSTRETCH_DISABLE;
  if (HAL_I2C_Init(&hi2c4) != HAL_OK)
  {
    Error_Handler();
  }

  /** Configure Analogue filter
  */
  if (HAL_I2CEx_ConfigAnalogFilter(&hi2c4, I2C_ANALOGFILTER_ENABLE) != HAL_OK)
  {
    Error_Handler();
  }

  /** Configure Digital filter
  */
  if (HAL_I2CEx_ConfigDigitalFilter(&hi2c4, 0) != HAL_OK)
  {
    Error_Handler();
  }

}

static void MX_SDMMC1_SD_Init(void)
{

  hsd1.Instance = SDMMC1;
  hsd1.Init.ClockEdge = SDMMC_CLOCK_EDGE_RISING;
  hsd1.Init.ClockPowerSave = SDMMC_CLOCK_POWER_SAVE_DISABLE;
  hsd1.Init.BusWide = SDMMC_BUS_WIDE_4B;
  hsd1.Init.HardwareFlowControl = SDMMC_HARDWARE_FLOW_CONTROL_DISABLE;
  hsd1.Init.ClockDiv = 4;
  if (HAL_SD_Init(&hsd1) != HAL_OK)
  {
    Error_Handler();
  }

}

static void MX_TIM3_Init(void)
{

  TIM_ClockConfigTypeDef sClockSourceConfig = {0};
  TIM_MasterConfigTypeDef sMasterConfig = {0};
  TIM_OC_InitTypeDef sConfigOC = {0};

  htim3.Instance = TIM3;
  htim3.Init.Prescaler = 10;
  htim3.Init.CounterMode = TIM_COUNTERMODE_UP;
  htim3.Init.Period = 255;
  htim3.Init.ClockDivision = TIM_CLOCKDIVISION_DIV1;
  htim3.Init.AutoReloadPreload = TIM_AUTORELOAD_PRELOAD_DISABLE;
  if (HAL_TIM_Base_Init(&htim3) != HAL_OK)
  {
    Error_Handler();
  }
  sClockSourceConfig.ClockSource = TIM_CLOCKSOURCE_INTERNAL;
  if (HAL_TIM_ConfigClockSource(&htim3, &sClockSourceConfig) != HAL_OK)
  {
    Error_Handler();
  }
  if (HAL_TIM_PWM_Init(&htim3) != HAL_OK)
  {
    Error_Handler();
  }
  sMasterConfig.MasterOutputTrigger = TIM_TRGO_RESET;
  sMasterConfig.MasterSlaveMode = TIM_MASTERSLAVEMODE_DISABLE;
  if (HAL_TIMEx_MasterConfigSynchronization(&htim3, &sMasterConfig) != HAL_OK)
  {
    Error_Handler();
  }
  sConfigOC.OCMode = TIM_OCMODE_PWM1;
  sConfigOC.Pulse = 0;
  sConfigOC.OCPolarity = TIM_OCPOLARITY_LOW;
  sConfigOC.OCFastMode = TIM_OCFAST_DISABLE;
  if (HAL_TIM_PWM_ConfigChannel(&htim3, &sConfigOC, TIM_CHANNEL_1) != HAL_OK)
  {
    Error_Handler();
  }
  if (HAL_TIM_PWM_ConfigChannel(&htim3, &sConfigOC, TIM_CHANNEL_2) != HAL_OK)
  {
    Error_Handler();
  }
  if (HAL_TIM_PWM_ConfigChannel(&htim3, &sConfigOC, TIM_CHANNEL_3) != HAL_OK)
  {
    Error_Handler();
  }
  HAL_TIM_MspPostInit(&htim3);

}

static void MX_TIM4_Init(void)
{

  TIM_ClockConfigTypeDef sClockSourceConfig = {0};
  TIM_MasterConfigTypeDef sMasterConfig = {0};

  htim4.Instance = TIM4;
  htim4.Init.Prescaler = 60000;
  htim4.Init.CounterMode = TIM_COUNTERMODE_UP;
  htim4.Init.Period = 65535;
  htim4.Init.ClockDivision = TIM_CLOCKDIVISION_DIV1;
  htim4.Init.AutoReloadPreload = TIM_AUTORELOAD_PRELOAD_DISABLE;
  if (HAL_TIM_Base_Init(&htim4) != HAL_OK)
  {
    Error_Handler();
  }
  sClockSourceConfig.ClockSource = TIM_CLOCKSOURCE_INTERNAL;
  if (HAL_TIM_ConfigClockSource(&htim4, &sClockSourceConfig) != HAL_OK)
  {
    Error_Handler();
  }
  sMasterConfig.MasterOutputTrigger = TIM_TRGO_RESET;
  sMasterConfig.MasterSlaveMode = TIM_MASTERSLAVEMODE_DISABLE;
  if (HAL_TIMEx_MasterConfigSynchronization(&htim4, &sMasterConfig) != HAL_OK)
  {
    Error_Handler();
  }

}

static void MX_UART4_Init(void)
{

  huart4.Instance = UART4;
  huart4.Init.BaudRate = 115200;
  huart4.Init.WordLength = UART_WORDLENGTH_8B;
  huart4.Init.StopBits = UART_STOPBITS_1;
  huart4.Init.Parity = UART_PARITY_NONE;
  huart4.Init.Mode = UART_MODE_TX_RX;
  huart4.Init.HwFlowCtl = UART_HWCONTROL_NONE;
  huart4.Init.OverSampling = UART_OVERSAMPLING_16;
  huart4.Init.OneBitSampling = UART_ONE_BIT_SAMPLE_DISABLE;
  huart4.Init.ClockPrescaler = UART_PRESCALER_DIV1;
  huart4.AdvancedInit.AdvFeatureInit = UART_ADVFEATURE_NO_INIT;
  if (HAL_UART_Init(&huart4) != HAL_OK)
  {
    Error_Handler();
  }
  if (HAL_UARTEx_SetTxFifoThreshold(&huart4, UART_TXFIFO_THRESHOLD_1_8) != HAL_OK)
  {
    Error_Handler();
  }
  if (HAL_UARTEx_SetRxFifoThreshold(&huart4, UART_RXFIFO_THRESHOLD_1_8) != HAL_OK)
  {
    Error_Handler();
  }
  if (HAL_UARTEx_DisableFifoMode(&huart4) != HAL_OK)
  {
    Error_Handler();
  }

}

static void MX_UART7_Init(void)
{

  huart7.Instance = UART7;
  huart7.Init.BaudRate = 115200;
  huart7.Init.WordLength = UART_WORDLENGTH_8B;
  huart7.Init.StopBits = UART_STOPBITS_1;
  huart7.Init.Parity = UART_PARITY_NONE;
  huart7.Init.Mode = UART_MODE_TX_RX;
  huart7.Init.HwFlowCtl = UART_HWCONTROL_RTS_CTS;
  huart7.Init.OverSampling = UART_OVERSAMPLING_16;
  huart7.Init.OneBitSampling = UART_ONE_BIT_SAMPLE_DISABLE;
  huart7.Init.ClockPrescaler = UART_PRESCALER_DIV1;
  huart7.AdvancedInit.AdvFeatureInit = UART_ADVFEATURE_NO_INIT;
  if (HAL_UART_Init(&huart7) != HAL_OK)
  {
    Error_Handler();
  }
  if (HAL_UARTEx_SetTxFifoThreshold(&huart7, UART_TXFIFO_THRESHOLD_1_8) != HAL_OK)
  {
    Error_Handler();
  }
  if (HAL_UARTEx_SetRxFifoThreshold(&huart7, UART_RXFIFO_THRESHOLD_1_8) != HAL_OK)
  {
    Error_Handler();
  }
  if (HAL_UARTEx_DisableFifoMode(&huart7) != HAL_OK)
  {
    Error_Handler();
  }

}

static void MX_UART8_Init(void)
{

  huart8.Instance = UART8;
  huart8.Init.BaudRate = 115200;
  huart8.Init.WordLength = UART_WORDLENGTH_8B;
  huart8.Init.StopBits = UART_STOPBITS_1;
  huart8.Init.Parity = UART_PARITY_NONE;
  huart8.Init.Mode = UART_MODE_TX_RX;
  huart8.Init.HwFlowCtl = UART_HWCONTROL_NONE;
  huart8.Init.OverSampling = UART_OVERSAMPLING_16;
  huart8.Init.OneBitSampling = UART_ONE_BIT_SAMPLE_DISABLE;
  huart8.Init.ClockPrescaler = UART_PRESCALER_DIV1;
  huart8.AdvancedInit.AdvFeatureInit = UART_ADVFEATURE_NO_INIT;
  if (HAL_UART_Init(&huart8) != HAL_OK)
  {
    Error_Handler();
  }
  if (HAL_UARTEx_SetTxFifoThreshold(&huart8, UART_TXFIFO_THRESHOLD_1_8) != HAL_OK)
  {
    Error_Handler();
  }
  if (HAL_UARTEx_SetRxFifoThreshold(&huart8, UART_RXFIFO_THRESHOLD_1_8) != HAL_OK)
  {
    Error_Handler();
  }
  if (HAL_UARTEx_DisableFifoMode(&huart8) != HAL_OK)
  {
    Error_Handler();
  }

}

static void MX_USART1_UART_Init(void)
{

  huart1.Instance = USART1;
  huart1.Init.BaudRate = 115200;
  huart1.Init.WordLength = UART_WORDLENGTH_8B;
  huart1.Init.StopBits = UART_STOPBITS_1;
  huart1.Init.Parity = UART_PARITY_NONE;
  huart1.Init.Mode = UART_MODE_TX_RX;
  huart1.Init.HwFlowCtl = UART_HWCONTROL_NONE;
  huart1.Init.OverSampling = UART_OVERSAMPLING_16;
  huart1.Init.OneBitSampling = UART_ONE_BIT_SAMPLE_DISABLE;
  huart1.Init.ClockPrescaler = UART_PRESCALER_DIV1;
  huart1.AdvancedInit.AdvFeatureInit = UART_ADVFEATURE_NO_INIT;
  if (HAL_UART_Init(&huart1) != HAL_OK)
  {
    Error_Handler();
  }
  if (HAL_UARTEx_SetTxFifoThreshold(&huart1, UART_TXFIFO_THRESHOLD_1_8) != HAL_OK)
  {
    Error_Handler();
  }
  if (HAL_UARTEx_SetRxFifoThreshold(&huart1, UART_RXFIFO_THRESHOLD_1_8) != HAL_OK)
  {
    Error_Handler();
  }
  if (HAL_UARTEx_DisableFifoMode(&huart1) != HAL_OK)
  {
    Error_Handler();
  }

}

static void MX_USART2_UART_Init(void)
{

  huart2.Instance = USART2;
  huart2.Init.BaudRate = 56800;
  huart2.Init.WordLength = UART_WORDLENGTH_8B;
  huart2.Init.StopBits = UART_STOPBITS_1;
  huart2.Init.Parity = UART_PARITY_NONE;
  huart2.Init.Mode = UART_MODE_TX_RX;
  huart2.Init.HwFlowCtl = UART_HWCONTROL_NONE;
  huart2.Init.OverSampling = UART_OVERSAMPLING_16;
  huart2.Init.OneBitSampling = UART_ONE_BIT_SAMPLE_DISABLE;
  huart2.Init.ClockPrescaler = UART_PRESCALER_DIV1;
  huart2.AdvancedInit.AdvFeatureInit = UART_ADVFEATURE_NO_INIT;
  if (HAL_UART_Init(&huart2) != HAL_OK)
  {
    Error_Handler();
  }
  if (HAL_UARTEx_SetTxFifoThreshold(&huart2, UART_TXFIFO_THRESHOLD_1_8) != HAL_OK)
  {
    Error_Handler();
  }
  if (HAL_UARTEx_SetRxFifoThreshold(&huart2, UART_RXFIFO_THRESHOLD_1_8) != HAL_OK)
  {
    Error_Handler();
  }
  if (HAL_UARTEx_DisableFifoMode(&huart2) != HAL_OK)
  {
    Error_Handler();
  }

}

static void MX_USART3_UART_Init(void)
{

  huart3.Instance = USART3;
  huart3.Init.BaudRate = 115200;
  huart3.Init.WordLength = UART_WORDLENGTH_8B;
  huart3.Init.StopBits = UART_STOPBITS_1;
  huart3.Init.Parity = UART_PARITY_NONE;
  huart3.Init.Mode = UART_MODE_TX_RX;
  huart3.Init.HwFlowCtl = UART_HWCONTROL_NONE;
  huart3.Init.OverSampling = UART_OVERSAMPLING_16;
  huart3.Init.OneBitSampling = UART_ONE_BIT_SAMPLE_DISABLE;
  huart3.Init.ClockPrescaler = UART_PRESCALER_DIV1;
  huart3.AdvancedInit.AdvFeatureInit = UART_ADVFEATURE_NO_INIT;
  if (HAL_RS485Ex_Init(&huart3, UART_DE_POLARITY_HIGH, 0, 0) != HAL_OK)
  {
    Error_Handler();
  }
  if (HAL_UARTEx_SetTxFifoThreshold(&huart3, UART_TXFIFO_THRESHOLD_1_8) != HAL_OK)
  {
    Error_Handler();
  }
  if (HAL_UARTEx_SetRxFifoThreshold(&huart3, UART_RXFIFO_THRESHOLD_1_8) != HAL_OK)
  {
    Error_Handler();
  }
  if (HAL_UARTEx_DisableFifoMode(&huart3) != HAL_OK)
  {
    Error_Handler();
  }

}

static void MX_USART6_UART_Init(void)
{

  huart6.Instance = USART6;
  huart6.Init.BaudRate = 115200;
  huart6.Init.WordLength = UART_WORDLENGTH_8B;
  huart6.Init.StopBits = UART_STOPBITS_1;
  huart6.Init.Parity = UART_PARITY_NONE;
  huart6.Init.Mode = UART_MODE_TX_RX;
  huart6.Init.HwFlowCtl = UART_HWCONTROL_NONE;
  huart6.Init.OverSampling = UART_OVERSAMPLING_16;
  huart6.Init.OneBitSampling = UART_ONE_BIT_SAMPLE_DISABLE;
  huart6.Init.ClockPrescaler = UART_PRESCALER_DIV1;
  huart6.AdvancedInit.AdvFeatureInit = UART_ADVFEATURE_NO_INIT;
  if (HAL_UART_Init(&huart6) != HAL_OK)
  {
    Error_Handler();
  }
  if (HAL_UARTEx_SetTxFifoThreshold(&huart6, UART_TXFIFO_THRESHOLD_1_8) != HAL_OK)
  {
    Error_Handler();
  }
  if (HAL_UARTEx_SetRxFifoThreshold(&huart6, UART_RXFIFO_THRESHOLD_1_8) != HAL_OK)
  {
    Error_Handler();
  }
  if (HAL_UARTEx_DisableFifoMode(&huart6) != HAL_OK)
  {
    Error_Handler();
  }

}

static void MX_DMA_Init(void)
{

  /* DMA controller clock enable */
  __HAL_RCC_DMA1_CLK_ENABLE();
  __HAL_RCC_DMA2_CLK_ENABLE();

  /* DMA interrupt init */
  /* DMA1_Stream0_IRQn interrupt configuration */
  HAL_NVIC_SetPriority(DMA1_Stream0_IRQn, 5, 0);
  HAL_NVIC_EnableIRQ(DMA1_Stream0_IRQn);
  /* DMA1_Stream1_IRQn interrupt configuration */
  HAL_NVIC_SetPriority(DMA1_Stream1_IRQn, 5, 0);
  HAL_NVIC_EnableIRQ(DMA1_Stream1_IRQn);
  /* DMA1_Stream2_IRQn interrupt configuration */
  HAL_NVIC_SetPriority(DMA1_Stream2_IRQn, 5, 0);
  HAL_NVIC_EnableIRQ(DMA1_Stream2_IRQn);
  /* DMA1_Stream3_IRQn interrupt configuration */
  HAL_NVIC_SetPriority(DMA1_Stream3_IRQn, 5, 0);
  HAL_NVIC_EnableIRQ(DMA1_Stream3_IRQn);
  /* DMA1_Stream4_IRQn interrupt configuration */
  HAL_NVIC_SetPriority(DMA1_Stream4_IRQn, 5, 0);
  HAL_NVIC_EnableIRQ(DMA1_Stream4_IRQn);
  /* DMA1_Stream5_IRQn interrupt configuration */
  HAL_NVIC_SetPriority(DMA1_Stream5_IRQn, 5, 0);
  HAL_NVIC_EnableIRQ(DMA1_Stream5_IRQn);
  /* DMA1_Stream6_IRQn interrupt configuration */
  HAL_NVIC_SetPriority(DMA1_Stream6_IRQn, 5, 0);
  HAL_NVIC_EnableIRQ(DMA1_Stream6_IRQn);
  /* DMA1_Stream7_IRQn interrupt configuration */
  HAL_NVIC_SetPriority(DMA1_Stream7_IRQn, 5, 0);
  HAL_NVIC_EnableIRQ(DMA1_Stream7_IRQn);
  /* DMA2_Stream0_IRQn interrupt configuration */
  HAL_NVIC_SetPriority(DMA2_Stream0_IRQn, 5, 0);
  HAL_NVIC_EnableIRQ(DMA2_Stream0_IRQn);
  /* DMA2_Stream1_IRQn interrupt configuration */
  HAL_NVIC_SetPriority(DMA2_Stream1_IRQn, 5, 0);
  HAL_NVIC_EnableIRQ(DMA2_Stream1_IRQn);
  /* DMA2_Stream2_IRQn interrupt configuration */
  HAL_NVIC_SetPriority(DMA2_Stream2_IRQn, 5, 0);
  HAL_NVIC_EnableIRQ(DMA2_Stream2_IRQn);
  /* DMA2_Stream3_IRQn interrupt configuration */
  HAL_NVIC_SetPriority(DMA2_Stream3_IRQn, 5, 0);
  HAL_NVIC_EnableIRQ(DMA2_Stream3_IRQn);
  /* DMA2_Stream4_IRQn interrupt configuration */
  HAL_NVIC_SetPriority(DMA2_Stream4_IRQn, 5, 0);
  HAL_NVIC_EnableIRQ(DMA2_Stream4_IRQn);
  /* DMA2_Stream5_IRQn interrupt configuration */
  HAL_NVIC_SetPriority(DMA2_Stream5_IRQn, 5, 0);
  HAL_NVIC_EnableIRQ(DMA2_Stream5_IRQn);
  /* DMA2_Stream6_IRQn interrupt configuration */
  HAL_NVIC_SetPriority(DMA2_Stream6_IRQn, 5, 0);
  HAL_NVIC_EnableIRQ(DMA2_Stream6_IRQn);
  /* DMA2_Stream7_IRQn interrupt configuration */
  HAL_NVIC_SetPriority(DMA2_Stream7_IRQn, 5, 0);
  HAL_NVIC_EnableIRQ(DMA2_Stream7_IRQn);

}

static void MX_GPIO_Init(void)
{
  GPIO_InitTypeDef GPIO_InitStruct = {0};

  /* GPIO Ports Clock Enable */
  __HAL_RCC_GPIOE_CLK_ENABLE();
  __HAL_RCC_GPIOH_CLK_ENABLE();
  __HAL_RCC_GPIOA_CLK_ENABLE();
  __HAL_RCC_GPIOC_CLK_ENABLE();
  __HAL_RCC_GPIOB_CLK_ENABLE();
  __HAL_RCC_GPIOD_CLK_ENABLE();

  /*Configure GPIO pin Output Level */
  HAL_GPIO_WritePin(GPIOE, EN_CM4_Pin|nBT_CM4_Pin|nWL_CM4_Pin, GPIO_PIN_SET);

  /*Configure GPIO pin Output Level */
  HAL_GPIO_WritePin(GPIOE, STOP_CM4_Pin|LED_STATUS_Pin|LED_ACTIVITY_Pin|LED_FAULT_Pin
                          |LED_USER1_Pin|LED_USER2_Pin, GPIO_PIN_RESET);

  /*Configure GPIO pin Output Level */
  HAL_GPIO_WritePin(nRST_IMU_GPIO_Port, nRST_IMU_Pin, GPIO_PIN_SET);

  /*Configure GPIO pin Output Level */
  HAL_GPIO_WritePin(WDISABLE_4G_GPIO_Port, WDISABLE_4G_Pin, GPIO_PIN_SET);

  /*Configure GPIO pin Output Level */
  HAL_GPIO_WritePin(PERST_4G_GPIO_Port, PERST_4G_Pin, GPIO_PIN_SET);

  /*Configure GPIO pin Output Level */
  HAL_GPIO_WritePin(GPIOB, LED_USER3_Pin|LED_UART_CM4_Pin, GPIO_PIN_RESET);

  /*Configure GPIO pin Output Level */
  HAL_GPIO_WritePin(GPIOD, SW_OUTPUT_Pin|SW_OVERWRITE_Pin|LED_UART_BACK_Pin|LED_FDCAN2_Pin
                          |LED_FDCAN1_Pin|LED_GNSS_Pin, GPIO_PIN_RESET);

  /*Configure GPIO pins : EN_CM4_Pin nBT_CM4_Pin nWL_CM4_Pin */
  GPIO_InitStruct.Pin = EN_CM4_Pin|nBT_CM4_Pin|nWL_CM4_Pin;
  GPIO_InitStruct.Mode = GPIO_MODE_OUTPUT_OD;
  GPIO_InitStruct.Pull = GPIO_NOPULL;
  GPIO_InitStruct.Speed = GPIO_SPEED_FREQ_LOW;
  HAL_GPIO_Init(GPIOE, &GPIO_InitStruct);

  /*Configure GPIO pin : PG_CM4_Pin */
  GPIO_InitStruct.Pin = PG_CM4_Pin;
  GPIO_InitStruct.Mode = GPIO_MODE_INPUT;
  GPIO_InitStruct.Pull = GPIO_NOPULL;
  HAL_GPIO_Init(PG_CM4_GPIO_Port, &GPIO_InitStruct);

  /*Configure GPIO pins : STOP_CM4_Pin LED_STATUS_Pin LED_ACTIVITY_Pin LED_FAULT_Pin
                           LED_USER1_Pin LED_USER2_Pin */
  GPIO_InitStruct.Pin = STOP_CM4_Pin|LED_STATUS_Pin|LED_ACTIVITY_Pin|LED_FAULT_Pin
                          |LED_USER1_Pin|LED_USER2_Pin;
  GPIO_InitStruct.Mode = GPIO_MODE_OUTPUT_PP;
  GPIO_InitStruct.Pull = GPIO_NOPULL;
  GPIO_InitStruct.Speed = GPIO_SPEED_FREQ_LOW;
  HAL_GPIO_Init(GPIOE, &GPIO_InitStruct);

  /*Configure GPIO pins : DRDY_IMU_Pin SD_PRESENCE_Pin */
  GPIO_InitStruct.Pin = DRDY_IMU_Pin|SD_PRESENCE_Pin;
  GPIO_InitStruct.Mode = GPIO_MODE_INPUT;
  GPIO_InitStruct.Pull = GPIO_NOPULL;
  HAL_GPIO_Init(GPIOA, &GPIO_InitStruct);

  /*Configure GPIO pin : nRST_IMU_Pin */
  GPIO_InitStruct.Pin = nRST_IMU_Pin;
  GPIO_InitStruct.Mode = GPIO_MODE_OUTPUT_OD;
  GPIO_InitStruct.Pull = GPIO_NOPULL;
  GPIO_InitStruct.Speed = GPIO_SPEED_FREQ_LOW;
  HAL_GPIO_Init(nRST_IMU_GPIO_Port, &GPIO_InitStruct);

  /*Configure GPIO pin : WAKE_4G_Pin */
  GPIO_InitStruct.Pin = WAKE_4G_Pin;
  GPIO_InitStruct.Mode = GPIO_MODE_INPUT;
  GPIO_InitStruct.Pull = GPIO_PULLUP;
  HAL_GPIO_Init(WAKE_4G_GPIO_Port, &GPIO_InitStruct);

  /*Configure GPIO pin : WDISABLE_4G_Pin */
  GPIO_InitStruct.Pin = WDISABLE_4G_Pin;
  GPIO_InitStruct.Mode = GPIO_MODE_OUTPUT_OD;
  GPIO_InitStruct.Pull = GPIO_NOPULL;
  GPIO_InitStruct.Speed = GPIO_SPEED_FREQ_LOW;
  HAL_GPIO_Init(WDISABLE_4G_GPIO_Port, &GPIO_InitStruct);

  /*Configure GPIO pin : PERST_4G_Pin */
  GPIO_InitStruct.Pin = PERST_4G_Pin;
  GPIO_InitStruct.Mode = GPIO_MODE_OUTPUT_OD;
  GPIO_InitStruct.Pull = GPIO_NOPULL;
  GPIO_InitStruct.Speed = GPIO_SPEED_FREQ_LOW;
  HAL_GPIO_Init(PERST_4G_GPIO_Port, &GPIO_InitStruct);

  /*Configure GPIO pins : DTR_4G_Pin WATER_DETECTION_Pin */
  GPIO_InitStruct.Pin = DTR_4G_Pin|WATER_DETECTION_Pin;
  GPIO_InitStruct.Mode = GPIO_MODE_IT_RISING;
  GPIO_InitStruct.Pull = GPIO_NOPULL;
  HAL_GPIO_Init(GPIOB, &GPIO_InitStruct);

  /*Configure GPIO pins : LED_USER3_Pin LED_UART_CM4_Pin */
  GPIO_InitStruct.Pin = LED_USER3_Pin|LED_UART_CM4_Pin;
  GPIO_InitStruct.Mode = GPIO_MODE_OUTPUT_PP;
  GPIO_InitStruct.Pull = GPIO_NOPULL;
  GPIO_InitStruct.Speed = GPIO_SPEED_FREQ_LOW;
  HAL_GPIO_Init(GPIOB, &GPIO_InitStruct);

  /*Configure GPIO pins : SW_OUTPUT_Pin SW_OVERWRITE_Pin LED_UART_BACK_Pin LED_FDCAN2_Pin
                           LED_FDCAN1_Pin LED_GNSS_Pin */
  GPIO_InitStruct.Pin = SW_OUTPUT_Pin|SW_OVERWRITE_Pin|LED_UART_BACK_Pin|LED_FDCAN2_Pin
                          |LED_FDCAN1_Pin|LED_GNSS_Pin;
  GPIO_InitStruct.Mode = GPIO_MODE_OUTPUT_PP;
  GPIO_InitStruct.Pull = GPIO_NOPULL;
  GPIO_InitStruct.Speed = GPIO_SPEED_FREQ_LOW;
  HAL_GPIO_Init(GPIOD, &GPIO_InitStruct);

  /*Configure GPIO pin : SW_INPUT_Pin */
  GPIO_InitStruct.Pin = SW_INPUT_Pin;
  GPIO_InitStruct.Mode = GPIO_MODE_INPUT;
  GPIO_InitStruct.Pull = GPIO_NOPULL;
  HAL_GPIO_Init(SW_INPUT_GPIO_Port, &GPIO_InitStruct);

  /*Configure GPIO pin : LED_RS485_Pin */
  GPIO_InitStruct.Pin = LED_RS485_Pin;
  GPIO_InitStruct.Mode = GPIO_MODE_IT_RISING;
  GPIO_InitStruct.Pull = GPIO_NOPULL;
  HAL_GPIO_Init(LED_RS485_GPIO_Port, &GPIO_InitStruct);

}

void TrajectoryTask(void *argument)
{
  /* USER CODE BEGIN 5 */
#ifdef AUTO_ID_ALLOCATION
  osDelay(AUTO_ID_DELAY); // leave some time to modules to configure themselves

  uint8_t base_address = STM32_HEAD;
  registers.WriteRegister<uint8_t>(REG_COM_ID_PROPAGATION, &base_address);

  bool success = true;
#ifdef GENERATOR_AUTO_MODULE_CONFIGURATION
  success = motion_generator.ConfigureModules();
#endif

#ifdef GENERATOR_AUTO_MODULE_CONTROLLER_ACTIVATION
  if (success)
	  success = motion_generator.ActivateModuleControllers();
#endif
#endif

  /* Infinite loop */
  for(;;)
  {
#ifdef USE_MOTION_GENERATOR
	  motion_generator.Spin();
#else
	  osDelay(1000);
#endif
  }
  /* USER CODE END 5 */
}

void SensorsTask(void *argument)
{
  /* USER CODE BEGIN SensorsTask */
  /* Infinite loop */
  for(;;)
  {
#ifdef USE_SENSORS
	  sensors.Spin();
#else
	  osDelay(1000);
#endif
  }
  /* USER CODE END SensorsTask */
}

void CommunicationTask(void *argument)
{
  /* USER CODE BEGIN CommunicationTask */
  /* Infinite loop */
  for(;;)
  {
	  communication.Spin();
  }
  /* USER CODE END CommunicationTask */
}

void LEDsTask(void *argument)
{
  /* USER CODE BEGIN LEDsTask */
  /* Infinite loop */
  for(;;)
  {
#ifdef USE_LEDS
	  leds.Spin();
#else
	  osDelay(1000);
#endif
  }
  /* USER CODE END LEDsTask */
}

void HAL_TIM_PeriodElapsedCallback(TIM_HandleTypeDef *htim)
{
  if (htim->Instance == TIM5) {
    HAL_IncTick();
  }
  /* USER CODE BEGIN Callback 1 */
  if (hardware_delay.AssignedTimer(htim)) {
    hardware_delay.TriggeredDelay();
  }
  /* USER CODE END Callback 1 */
}

void Error_Handler(void)
{
  __disable_irq();
  while (1)
  {
  }
}
